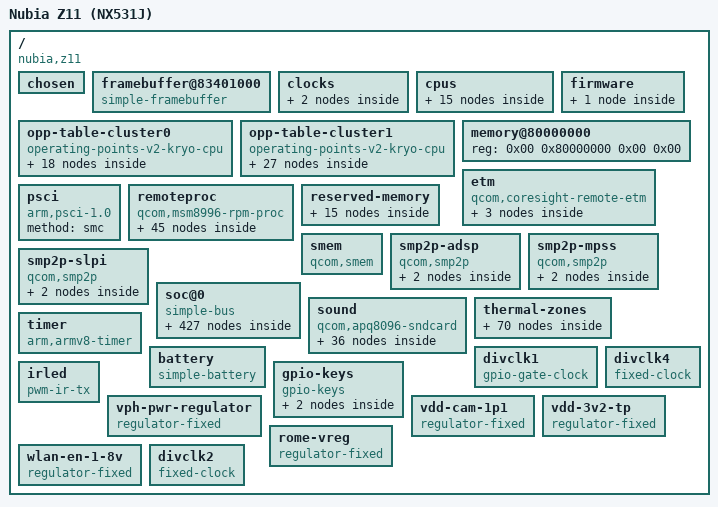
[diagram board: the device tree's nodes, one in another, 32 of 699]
/dts-v1/;

/ {
	interrupt-parent = <0x01>;
	#address-cells = <0x02>;
	#size-cells = <0x02>;
	model = "Nubia Z11 (NX531J)";
	compatible = "nubia,z11", "qcom,msm8996";
	chassis-type = "handset";
	qcom,msm-id = <0xf6 0x30001>;
	qcom,pmic-id = <0x20009 0x2000a 0x00 0x00>;
	qcom,board-id = <0x1f 0x00 0x20 0x00>;

	chosen {
	};

	framebuffer@83401000 {
		compatible = "simple-framebuffer";
		reg = <0x00 0x83401000 0x00 0x7e9000>;
		width = <0x438>;
		height = <0x780>;
		stride = <0x10e0>;
		format = "a8r8g8b8";
		status = "okay";
	};

	clocks {

		xo-board {
			compatible = "fixed-clock";
			#clock-cells = <0x00>;
			clock-frequency = <0x124f800>;
			clock-output-names = "xo_board";
			phandle = <0x12>;
		};

		sleep-clk {
			compatible = "fixed-clock";
			#clock-cells = <0x00>;
			clock-frequency = <0x7ffc>;
			clock-output-names = "sleep_clk";
			phandle = <0x20>;
		};
	};

	cpus {
		#address-cells = <0x02>;
		#size-cells = <0x00>;

		cpu@0 {
			device_type = "cpu";
			compatible = "qcom,kryo";
			reg = <0x00 0x00>;
			enable-method = "psci";
			cpu-idle-states = <0x02>;
			capacity-dmips-mhz = <0x400>;
			clocks = <0x03 0x00>;
			interconnects = <0x04 0x00 0x04 0x01>;
			operating-points-v2 = <0x05>;
			#cooling-cells = <0x02>;
			next-level-cache = <0x06>;
			phandle = <0x09>;

			l2-cache {
				compatible = "cache";
				cache-level = <0x02>;
				cache-unified;
				phandle = <0x06>;
			};
		};

		cpu@1 {
			device_type = "cpu";
			compatible = "qcom,kryo";
			reg = <0x00 0x01>;
			enable-method = "psci";
			cpu-idle-states = <0x02>;
			capacity-dmips-mhz = <0x400>;
			clocks = <0x03 0x00>;
			interconnects = <0x04 0x00 0x04 0x01>;
			operating-points-v2 = <0x05>;
			#cooling-cells = <0x02>;
			next-level-cache = <0x06>;
			phandle = <0x0a>;
		};

		cpu@100 {
			device_type = "cpu";
			compatible = "qcom,kryo";
			reg = <0x00 0x100>;
			enable-method = "psci";
			cpu-idle-states = <0x02>;
			capacity-dmips-mhz = <0x400>;
			clocks = <0x03 0x01>;
			interconnects = <0x04 0x00 0x04 0x01>;
			operating-points-v2 = <0x07>;
			#cooling-cells = <0x02>;
			next-level-cache = <0x08>;
			phandle = <0x0b>;

			l2-cache {
				compatible = "cache";
				cache-level = <0x02>;
				cache-unified;
				phandle = <0x08>;
			};
		};

		cpu@101 {
			device_type = "cpu";
			compatible = "qcom,kryo";
			reg = <0x00 0x101>;
			enable-method = "psci";
			cpu-idle-states = <0x02>;
			capacity-dmips-mhz = <0x400>;
			clocks = <0x03 0x01>;
			interconnects = <0x04 0x00 0x04 0x01>;
			operating-points-v2 = <0x07>;
			#cooling-cells = <0x02>;
			next-level-cache = <0x08>;
			phandle = <0x0c>;
		};

		cpu-map {

			cluster0 {

				core0 {
					cpu = <0x09>;
				};

				core1 {
					cpu = <0x0a>;
				};
			};

			cluster1 {

				core0 {
					cpu = <0x0b>;
				};

				core1 {
					cpu = <0x0c>;
				};
			};
		};

		idle-states {
			entry-method = "psci";

			cpu-sleep-0 {
				compatible = "arm,idle-state";
				idle-state-name = "standalone-power-collapse";
				arm,psci-suspend-param = <0x04>;
				entry-latency-us = <0x82>;
				exit-latency-us = <0x50>;
				min-residency-us = <0x12c>;
				phandle = <0x02>;
			};
		};
	};

	opp-table-cluster0 {
		compatible = "operating-points-v2-kryo-cpu";
		nvmem-cells = <0x0d>;
		opp-shared;
		phandle = <0x05>;

		opp-307200000 {
			opp-hz = <0x00 0x124f8000>;
			opp-supported-hw = <0x0f>;
			clock-latency-ns = <0x30d40>;
			opp-peak-kBps = <0x4b000>;
		};

		opp-422400000 {
			opp-hz = <0x00 0x192d5000>;
			opp-supported-hw = <0x0f>;
			clock-latency-ns = <0x30d40>;
			opp-peak-kBps = <0x4b000>;
		};

		opp-480000000 {
			opp-hz = <0x00 0x1c9c3800>;
			opp-supported-hw = <0x0f>;
			clock-latency-ns = <0x30d40>;
			opp-peak-kBps = <0x4b000>;
		};

		opp-556800000 {
			opp-hz = <0x00 0x21301800>;
			opp-supported-hw = <0x0f>;
			clock-latency-ns = <0x30d40>;
			opp-peak-kBps = <0x4b000>;
		};

		opp-652800000 {
			opp-hz = <0x00 0x26e8f000>;
			opp-supported-hw = <0x0f>;
			clock-latency-ns = <0x30d40>;
			opp-peak-kBps = <0x5dc00>;
		};

		opp-729600000 {
			opp-hz = <0x00 0x2b7cd000>;
			opp-supported-hw = <0x0f>;
			clock-latency-ns = <0x30d40>;
			opp-peak-kBps = "", "\a\b";
		};

		opp-844800000 {
			opp-hz = <0x00 0x325aa000>;
			opp-supported-hw = <0x0f>;
			clock-latency-ns = <0x30d40>;
			opp-peak-kBps = "", "\b4";
		};

		opp-960000000 {
			opp-hz = <0x00 0x39387000>;
			opp-supported-hw = <0x0f>;
			clock-latency-ns = <0x30d40>;
			opp-peak-kBps = "", "\nA";
		};

		opp-1036800000 {
			opp-hz = <0x00 0x3dcc5000>;
			opp-supported-hw = <0x0f>;
			clock-latency-ns = <0x30d40>;
			opp-peak-kBps = "", "\nA";
		};

		opp-1113600000 {
			opp-hz = <0x00 0x42603000>;
			opp-supported-hw = <0x0f>;
			clock-latency-ns = <0x30d40>;
			opp-peak-kBps = <0xc9900>;
		};

		opp-1190400000 {
			opp-hz = <0x00 0x46f41000>;
			opp-supported-hw = <0x0f>;
			clock-latency-ns = <0x30d40>;
			opp-peak-kBps = <0xc9900>;
		};

		opp-1228800000 {
			opp-hz = <0x00 0x493e0000>;
			opp-supported-hw = <0x0f>;
			clock-latency-ns = <0x30d40>;
			opp-peak-kBps = <0xdc500>;
		};

		opp-1324800000 {
			opp-hz = <0x00 0x4ef6d800>;
			opp-supported-hw = <0x0d>;
			clock-latency-ns = <0x30d40>;
			opp-peak-kBps = <0x101d00>;
		};

		opp-1363200000 {
			opp-hz = <0x00 0x5140c800>;
			opp-supported-hw = <0x02>;
			clock-latency-ns = <0x30d40>;
			opp-peak-kBps = <0x114900>;
		};

		opp-1401600000 {
			opp-hz = <0x00 0x538ab800>;
			opp-supported-hw = <0x0d>;
			clock-latency-ns = <0x30d40>;
			opp-peak-kBps = <0x114900>;
		};

		opp-1478400000 {
			opp-hz = <0x00 0x581e9800>;
			opp-supported-hw = <0x09>;
			clock-latency-ns = <0x30d40>;
			opp-peak-kBps = <0x122a00>;
		};

		opp-1497600000 {
			opp-hz = <0x00 0x59439000>;
			opp-supported-hw = <0x04>;
			clock-latency-ns = <0x30d40>;
			opp-peak-kBps = <0x13ec00>;
		};

		opp-1593600000 {
			opp-hz = <0x00 0x5efc6800>;
			opp-supported-hw = <0x09>;
			clock-latency-ns = <0x30d40>;
			opp-peak-kBps = <0x151800>;
		};
	};

	opp-table-cluster1 {
		compatible = "operating-points-v2-kryo-cpu";
		nvmem-cells = <0x0d>;
		opp-shared;
		phandle = <0x07>;

		opp-307200000 {
			opp-hz = <0x00 0x124f8000>;
			opp-supported-hw = <0x0f>;
			clock-latency-ns = <0x30d40>;
			opp-peak-kBps = <0x4b000>;
		};

		opp-403200000 {
			opp-hz = <0x00 0x18085800>;
			opp-supported-hw = <0x0f>;
			clock-latency-ns = <0x30d40>;
			opp-peak-kBps = <0x4b000>;
		};

		opp-480000000 {
			opp-hz = <0x00 0x1c9c3800>;
			opp-supported-hw = <0x0f>;
			clock-latency-ns = <0x30d40>;
			opp-peak-kBps = <0x4b000>;
		};

		opp-556800000 {
			opp-hz = <0x00 0x21301800>;
			opp-supported-hw = <0x0f>;
			clock-latency-ns = <0x30d40>;
			opp-peak-kBps = <0x4b000>;
		};

		opp-652800000 {
			opp-hz = <0x00 0x26e8f000>;
			opp-supported-hw = <0x0f>;
			clock-latency-ns = <0x30d40>;
			opp-peak-kBps = <0x4b000>;
		};

		opp-729600000 {
			opp-hz = <0x00 0x2b7cd000>;
			opp-supported-hw = <0x0f>;
			clock-latency-ns = <0x30d40>;
			opp-peak-kBps = <0x4b000>;
		};

		opp-806400000 {
			opp-hz = <0x00 0x3010b000>;
			opp-supported-hw = <0x0f>;
			clock-latency-ns = <0x30d40>;
			opp-peak-kBps = <0x5dc00>;
		};

		opp-883200000 {
			opp-hz = <0x00 0x34a49000>;
			opp-supported-hw = <0x0f>;
			clock-latency-ns = <0x30d40>;
			opp-peak-kBps = "", "\a\b";
		};

		opp-940800000 {
			opp-hz = <0x00 0x38137800>;
			opp-supported-hw = <0x0f>;
			clock-latency-ns = <0x30d40>;
			opp-peak-kBps = "", "\b4";
		};

		opp-1036800000 {
			opp-hz = <0x00 0x3dcc5000>;
			opp-supported-hw = <0x0f>;
			clock-latency-ns = <0x30d40>;
			opp-peak-kBps = <0x91500>;
		};

		opp-1113600000 {
			opp-hz = <0x00 0x42603000>;
			opp-supported-hw = <0x0f>;
			clock-latency-ns = <0x30d40>;
			opp-peak-kBps = "", "\nA";
		};

		opp-1190400000 {
			opp-hz = <0x00 0x46f41000>;
			opp-supported-hw = <0x0f>;
			clock-latency-ns = <0x30d40>;
			opp-peak-kBps = "", "\nA";
		};

		opp-1248000000 {
			opp-hz = <0x00 0x4a62f800>;
			opp-supported-hw = <0x0f>;
			clock-latency-ns = <0x30d40>;
			opp-peak-kBps = "", "\vm";
		};

		opp-1324800000 {
			opp-hz = <0x00 0x4ef6d800>;
			opp-supported-hw = <0x0f>;
			clock-latency-ns = <0x30d40>;
			opp-peak-kBps = <0xc9900>;
		};

		opp-1401600000 {
			opp-hz = <0x00 0x538ab800>;
			opp-supported-hw = <0x0f>;
			clock-latency-ns = <0x30d40>;
			opp-peak-kBps = <0xdc500>;
		};

		opp-1478400000 {
			opp-hz = <0x00 0x581e9800>;
			opp-supported-hw = <0x0f>;
			clock-latency-ns = <0x30d40>;
			opp-peak-kBps = <0xef100>;
		};

		opp-1555200000 {
			opp-hz = <0x00 0x5cb27800>;
			opp-supported-hw = <0x0f>;
			clock-latency-ns = <0x30d40>;
			opp-peak-kBps = <0x101d00>;
		};

		opp-1632000000 {
			opp-hz = <0x00 0x61465800>;
			opp-supported-hw = <0x0f>;
			clock-latency-ns = <0x30d40>;
			opp-peak-kBps = <0x122a00>;
		};

		opp-1708800000 {
			opp-hz = <0x00 0x65da3800>;
			opp-supported-hw = <0x0f>;
			clock-latency-ns = <0x30d40>;
			opp-peak-kBps = <0x12c000>;
		};

		opp-1785600000 {
			opp-hz = <0x00 0x6a6e1800>;
			opp-supported-hw = <0x0f>;
			clock-latency-ns = <0x30d40>;
			opp-peak-kBps = <0x13ec00>;
		};

		opp-1804800000 {
			opp-hz = <0x00 0x6b931000>;
			opp-supported-hw = <0x0e>;
			clock-latency-ns = <0x30d40>;
			opp-peak-kBps = <0x13ec00>;
		};

		opp-1824000000 {
			opp-hz = <0x00 0x6cb80800>;
			opp-supported-hw = <0x01>;
			clock-latency-ns = <0x30d40>;
			opp-peak-kBps = <0x151800>;
		};

		opp-1900800000 {
			opp-hz = <0x00 0x714be800>;
			opp-supported-hw = <0x04>;
			clock-latency-ns = <0x30d40>;
			opp-peak-kBps = <0x13ec00>;
		};

		opp-1920000000 {
			opp-hz = <0x00 0x7270e000>;
			opp-supported-hw = <0x01>;
			clock-latency-ns = <0x30d40>;
			opp-peak-kBps = <0x164400>;
		};

		opp-1996800000 {
			opp-hz = <0x00 0x7704c000>;
			opp-supported-hw = <0x01>;
			clock-latency-ns = <0x30d40>;
			opp-peak-kBps = <0x185100>;
		};

		opp-2073600000 {
			opp-hz = <0x00 0x7b98a000>;
			opp-supported-hw = <0x01>;
			clock-latency-ns = <0x30d40>;
			opp-peak-kBps = <0x185100>;
		};

		opp-2150400000 {
			opp-hz = <0x00 0x802c8000>;
			opp-supported-hw = <0x01>;
			clock-latency-ns = <0x30d40>;
			opp-peak-kBps = <0x185100>;
		};
	};

	firmware {

		scm {
			compatible = "qcom,scm-msm8996", "qcom,scm";
			qcom,dload-mode = <0x0e 0x13000>;
		};
	};

	memory@80000000 {
		device_type = "memory";
		reg = <0x00 0x80000000 0x00 0x00>;
	};

	etm {
		compatible = "qcom,coresight-remote-etm";

		out-ports {

			port {

				endpoint {
					remote-endpoint = <0x0f>;
					phandle = <0x6e>;
				};
			};
		};
	};

	psci {
		compatible = "arm,psci-1.0";
		method = "smc";
	};

	remoteproc {
		compatible = "qcom,msm8996-rpm-proc", "qcom,rpm-proc";

		glink-edge {
			compatible = "qcom,glink-rpm";
			interrupts = <0x00 0xa8 0x01>;
			qcom,rpm-msg-ram = <0x10>;
			mboxes = <0x11 0x00>;

			rpm-requests {
				compatible = "qcom,rpm-msm8996", "qcom,glink-smd-rpm";
				qcom,glink-channels = "rpm_requests";

				clock-controller {
					compatible = "qcom,rpmcc-msm8996", "qcom,rpmcc";
					#clock-cells = <0x01>;
					clocks = <0x12>;
					clock-names = "xo";
					phandle = <0x1f>;
				};

				power-controller {
					compatible = "qcom,msm8996-rpmpd";
					#power-domain-cells = <0x01>;
					operating-points-v2 = <0x13>;
					phandle = <0x60>;

					opp-table {
						compatible = "operating-points-v2";
						phandle = <0x13>;

						opp1 {
							opp-level = <0x01>;
						};

						opp2 {
							opp-level = <0x02>;
						};

						opp3 {
							opp-level = <0x03>;
						};

						opp4 {
							opp-level = <0x04>;
						};

						opp5 {
							opp-level = <0x05>;
						};

						opp6 {
							opp-level = <0x06>;
						};
					};
				};

				regulators-0 {
					compatible = "qcom,rpm-pm8994-regulators";
					vdd_s1-supply = <0x14>;
					vdd_s2-supply = <0x14>;
					vdd_s3-supply = <0x14>;
					vdd_s4-supply = <0x14>;
					vdd_s5-supply = <0x14>;
					vdd_s6-supply = <0x14>;
					vdd_s7-supply = <0x14>;
					vdd_s8-supply = <0x14>;
					vdd_s9-supply = <0x14>;
					vdd_s10-supply = <0x14>;
					vdd_s11-supply = <0x14>;
					vdd_s12-supply = <0x14>;
					vdd_l1-supply = <0x15>;
					vdd_l2_l26_l28-supply = <0x16>;
					vdd_l3_l11-supply = <0x16>;
					vdd_l4_l27_l31-supply = <0x16>;
					vdd_l5_l7-supply = <0x17>;
					vdd_l6_l12_l32-supply = <0x17>;
					vdd_l8_l16_l30-supply = <0x14>;
					vdd_l9_l10_l18_l22-supply = <0x18>;
					vdd_l13_l19_l23_l24-supply = <0x18>;
					vdd_l14_l15-supply = <0x17>;
					vdd_l17_l29-supply = <0x18>;
					vdd_l20_l21-supply = <0x18>;
					vdd_l25-supply = <0x16>;
					vdd_lvs1_2-supply = <0x19>;

					s3 {
						regulator-name = "vreg_s3a_1p3";
						regulator-min-microvolt = <0x13d620>;
						regulator-max-microvolt = <0x13d620>;
						regulator-always-on;
						phandle = <0x16>;
					};

					s4 {
						regulator-name = "vreg_s4a_1p8";
						regulator-min-microvolt = <0x1b7740>;
						regulator-max-microvolt = <0x1b7740>;
						regulator-allow-set-load;
						regulator-always-on;
						phandle = <0x19>;
					};

					s5 {
						regulator-name = "vreg_s5a_2p15";
						regulator-min-microvolt = <0x20ce70>;
						regulator-max-microvolt = <0x20ce70>;
						phandle = <0x17>;
					};

					s7 {
						regulator-name = "vreg_s7a_0p8";
						regulator-min-microvolt = "", "\f5";
						regulator-max-microvolt = "", "\f5";
					};

					l1 {
						regulator-name = "vreg_l1a_1p0";
						regulator-min-microvolt = <0xf4240>;
						regulator-max-microvolt = <0xf4240>;
					};

					l2 {
						regulator-name = "vreg_l2a_1p25";
						regulator-min-microvolt = <0x1312d0>;
						regulator-max-microvolt = <0x1312d0>;
						phandle = <0x39>;
					};

					l4 {
						regulator-name = "vreg_l4a_1p225";
						regulator-min-microvolt = <0x12b128>;
						regulator-max-microvolt = <0x12b128>;
					};

					l6 {
						regulator-name = "vreg_l6a_1p8";
						regulator-min-microvolt = <0x1b7740>;
						regulator-max-microvolt = <0x1b7740>;
						phandle = <0xa9>;
					};

					l8 {
						regulator-name = "vreg_l8a_1p8";
						regulator-min-microvolt = <0x1b7740>;
						regulator-max-microvolt = <0x1b7740>;
					};

					l9 {
						regulator-name = "vreg_l9a_1p8";
						regulator-min-microvolt = <0x1b7740>;
						regulator-max-microvolt = <0x1b7740>;
					};

					l10 {
						regulator-name = "vreg_l10a_1p8";
						regulator-min-microvolt = <0x1b7740>;
						regulator-max-microvolt = <0x1b7740>;
					};

					l12 {
						regulator-name = "vreg_l12a_1p8";
						regulator-min-microvolt = <0x1b7740>;
						regulator-max-microvolt = <0x1b7740>;
						regulator-allow-set-load;
						phandle = <0x1e>;
					};

					l13 {
						regulator-name = "vreg_l13a_2p95";
						regulator-min-microvolt = <0x1b7740>;
						regulator-max-microvolt = <0x2d0370>;
					};

					l14 {
						regulator-name = "vreg_l14a_1p8";
						regulator-min-microvolt = <0x1b7740>;
						regulator-max-microvolt = <0x1b7740>;
						phandle = <0x34>;
					};

					l15 {
						regulator-name = "vreg_l15a_1p8";
						regulator-min-microvolt = <0x1b7740>;
						regulator-max-microvolt = <0x1b7740>;
					};

					l16 {
						regulator-name = "vreg_l16a_2p7";
						regulator-min-microvolt = <0x2932e0>;
						regulator-max-microvolt = <0x2932e0>;
					};

					l19 {
						regulator-name = "vreg_l19a_3p3";
						regulator-min-microvolt = <0x2dc6c0>;
						regulator-max-microvolt = <0x2dc6c0>;
						phandle = <0x33>;
					};

					l20 {
						regulator-name = "vreg_l20a_2p95";
						regulator-min-microvolt = <0x2d0370>;
						regulator-max-microvolt = <0x2d0370>;
						regulator-allow-set-load;
						phandle = <0x55>;
					};

					l21 {
						regulator-name = "vreg_l21a_2p95";
						regulator-min-microvolt = <0x325aa0>;
						regulator-max-microvolt = <0x325aa0>;
						regulator-always-on;
					};

					l23 {
						regulator-name = "vreg_l23a_2p8";
						regulator-min-microvolt = <0x2ab980>;
						regulator-max-microvolt = <0x2ab980>;
					};

					l24 {
						regulator-name = "vreg_l24a_3p075";
						regulator-min-microvolt = <0x2eebb8>;
						regulator-max-microvolt = <0x2eebb8>;
						phandle = <0x8c>;
					};

					l25 {
						regulator-name = "vreg_l25a_1p2";
						regulator-min-microvolt = <0x124f80>;
						regulator-max-microvolt = <0x124f80>;
						regulator-allow-set-load;
						phandle = <0x56>;
					};

					l27 {
						regulator-name = "vreg_l27a_1p2";
						regulator-min-microvolt = <0x124f80>;
						regulator-max-microvolt = <0x124f80>;
					};

					l28 {
						regulator-name = "vreg_l28a_0p925";
						regulator-min-microvolt = <0xe1d48>;
						regulator-max-microvolt = <0xe1d48>;
						regulator-allow-set-load;
						phandle = <0x1d>;
					};

					l30 {
						regulator-name = "vreg_l30a_1p8";
						regulator-min-microvolt = <0x1b7740>;
						regulator-max-microvolt = <0x1b7740>;
						regulator-always-on;
					};

					l32 {
						regulator-name = "vreg_l32a_1p8";
						regulator-min-microvolt = <0x1b7740>;
						regulator-max-microvolt = <0x1b7740>;
					};

					lvs1 {
						regulator-name = "vreg_lvs1a_1p8";
						regulator-min-microvolt = <0x1b7740>;
						regulator-max-microvolt = <0x1b7740>;
					};

					lvs2 {
						regulator-name = "vreg_lvs2a_1p8";
						regulator-min-microvolt = <0x1b7740>;
						regulator-max-microvolt = <0x1b7740>;
						phandle = <0x61>;
					};

					l17 {
						regulator-name = "vreg_l17a_2p8";
						regulator-min-microvolt = <0x2625a0>;
						regulator-max-microvolt = <0x2625a0>;
					};

					l29 {
						regulator-name = "vreg_l29a_2p7";
						regulator-min-microvolt = <0x2ab980>;
						regulator-max-microvolt = <0x2ab980>;
					};
				};

				regulators-1 {
					compatible = "qcom,rpm-pmi8994-regulators";
					vdd_s1-supply = <0x14>;
					vdd_s2-supply = <0x14>;
					vdd_s3-supply = <0x14>;
					vdd_bst_byp-supply = <0x14>;

					s1 {
						regulator-name = "vreg_s1b_1p025";
						regulator-min-microvolt = <0xfa3e8>;
						regulator-max-microvolt = <0xfa3e8>;
						phandle = <0x15>;
					};

					boost-bypass {
						regulator-name = "vph_pwr_bbyp";
						regulator-min-microvolt = <0x3010b0>;
						regulator-max-microvolt = <0x36ee80>;
						phandle = <0x18>;
					};
				};
			};
		};
	};

	reserved-memory {
		#address-cells = <0x02>;
		#size-cells = <0x02>;
		ranges;

		memory@85800000 {
			reg = <0x00 0x85800000 0x00 0x600000>;
			no-map;
				splash_region: splash@83400000 {
			reg = <0x00 0x83400000 0x00 0x23ff000>;
		};
};

		memory@85e00000 {
			reg = <0x00 0x85e00000 0x00 0x200000>;
			no-map;
		};

		smem-mem@86000000 {
			reg = <0x00 0x86000000 0x00 0x200000>;
			no-map;
			phandle = <0x1a>;
		};

		memory@86200000 {
			reg = <0x00 0x86200000 0x00 0x2600000>;
			no-map;
		};

		mpss-metadata {
			alloc-ranges = <0x00 0xa0000000 0x00 0x20000000>;
			size = <0x00 0x4000>;
			no-map;
			phandle = <0x67>;
		};

		memory@88800000 {
			reg = <0x00 0x88800000 0x00 0x1400000>;
			no-map;
		};

		mpss@89c00000 {
			reg = <0x00 0x89c00000 0x00 0x6200000>;
			no-map;
			phandle = <0x66>;
		};

		adsp@8fe00000 {
			reg = <0x00 0x8fe00000 0x00 0x1b00000>;
			no-map;
			phandle = <0xb7>;
		};

		slpi@91900000 {
			reg = <0x00 0x91900000 0x00 0xa00000>;
			no-map;
			phandle = <0x5e>;
		};

		gpu@92300000 {
			compatible = "shared-dma-pool";
			reg = <0x00 0x92300000 0x00 0x2000>;
			no-map;
			phandle = <0x43>;
		};

		venus@92400000 {
			reg = <0x00 0x92400000 0x00 0x500000>;
			no-map;
			phandle = <0x5c>;
		};

		ramoops@92900000 {
			compatible = "ramoops";
			reg = <0x00 0x92900000 0x00 0x100000>;
			no-map;
			record-size = <0x8000>;
			console-size = <0x80000>;
			ftrace-size = <0x20000>;
			pmsg-size = <0x40000>;
		};

		rmtfs@f6c00000 {
			compatible = "qcom,rmtfs-mem";
			reg = <0x00 0xf6c00000 0x00 0x200000>;
			no-map;
			qcom,client-id = <0x01>;
			qcom,vmid = <0x0f>;
		};

		mba@f6f00000 {
			reg = <0x00 0xf6f00000 0x00 0x100000>;
			no-map;
			phandle = <0x65>;
		};
	};

	smem {
		compatible = "qcom,smem";
		memory-region = <0x1a>;
		hwlocks = <0x1b 0x03>;
	};

	smp2p-adsp {
		compatible = "qcom,smp2p";
		qcom,smem = <0x1bb 0x1ad>;
		interrupts = <0x00 0x9e 0x01>;
		mboxes = <0x11 0x0a>;
		qcom,local-pid = <0x00>;
		qcom,remote-pid = <0x02>;

		master-kernel {
			qcom,entry-name = "master-kernel";
			#qcom,smem-state-cells = <0x01>;
			phandle = <0xb8>;
		};

		slave-kernel {
			qcom,entry-name = "slave-kernel";
			interrupt-controller;
			#interrupt-cells = <0x02>;
			phandle = <0xb6>;
		};
	};

	smp2p-mpss {
		compatible = "qcom,smp2p";
		qcom,smem = <0x1b3 0x1ac>;
		interrupts = <0x00 0x1c3 0x01>;
		mboxes = <0x11 0x0e>;
		qcom,local-pid = <0x00>;
		qcom,remote-pid = <0x01>;

		master-kernel {
			qcom,entry-name = "master-kernel";
			#qcom,smem-state-cells = <0x01>;
			phandle = <0x63>;
		};

		slave-kernel {
			qcom,entry-name = "slave-kernel";
			interrupt-controller;
			#interrupt-cells = <0x02>;
			phandle = <0x62>;
		};
	};

	smp2p-slpi {
		compatible = "qcom,smp2p";
		qcom,smem = <0x1e1 0x1ae>;
		interrupts = <0x00 0xb2 0x01>;
		mboxes = <0x11 0x1a>;
		qcom,local-pid = <0x00>;
		qcom,remote-pid = <0x03>;

		master-kernel {
			qcom,entry-name = "master-kernel";
			#qcom,smem-state-cells = <0x01>;
			phandle = <0x5f>;
		};

		slave-kernel {
			qcom,entry-name = "slave-kernel";
			interrupt-controller;
			#interrupt-cells = <0x02>;
			phandle = <0x5d>;
		};
	};

	soc@0 {
		#address-cells = <0x01>;
		#size-cells = <0x01>;
		ranges = <0x00 0x00 0x00 0xffffffff>;
		compatible = "simple-bus";

		phy-wrapper@34000 {
			compatible = "qcom,msm8996-qmp-pcie-phy";
			reg = <0x34000 0x488>;
			#address-cells = <0x01>;
			#size-cells = <0x01>;
			ranges = <0x00 0x34000 0x4000>;
			clocks = <0x1c 0xc0 0x1c 0xbf 0x1c 0xd8>;
			clock-names = "aux", "cfg_ahb", "ref";
			resets = <0x1c 0x55 0x1c 0x65 0x1c 0x66>;
			reset-names = "phy", "common", "cfg";
			status = "okay";
			vdda-phy-supply = <0x1d>;
			vdda-pll-supply = <0x1e>;

			phy@1000 {
				reg = <0x1000 0x130 0x1200 0x200 0x1400 0x1dc>;
				clocks = <0x1c 0xb4>;
				clock-names = "pipe0";
				resets = <0x1c 0x50>;
				reset-names = "lane0";
				#clock-cells = <0x00>;
				clock-output-names = "pcie_0_pipe_clk_src";
				#phy-cells = <0x00>;
				phandle = <0x21>;
			};

			phy@2000 {
				reg = <0x2000 0x130 0x2200 0x200 0x2400 0x1dc>;
				clocks = <0x1c 0xb9>;
				clock-names = "pipe1";
				resets = <0x1c 0x52>;
				reset-names = "lane1";
				#clock-cells = <0x00>;
				clock-output-names = "pcie_1_pipe_clk_src";
				#phy-cells = <0x00>;
				phandle = <0x22>;
			};

			phy@3000 {
				reg = <0x3000 0x130 0x3200 0x200 0x3400 0x1dc>;
				clocks = <0x1c 0xbe>;
				clock-names = "pipe2";
				resets = <0x1c 0x54>;
				reset-names = "lane2";
				#clock-cells = <0x00>;
				clock-output-names = "pcie_2_pipe_clk_src";
				#phy-cells = <0x00>;
				phandle = <0x23>;
			};
		};

		sram@68000 {
			compatible = "qcom,rpm-msg-ram";
			reg = <0x68000 0x6000>;
			phandle = <0x10>;
		};

		qfprom@74000 {
			compatible = "qcom,msm8996-qfprom", "qcom,qfprom";
			reg = <0x74000 0x8ff>;
			#address-cells = <0x01>;
			#size-cells = <0x01>;

			hstx-trim@24e {
				reg = <0x24e 0x02>;
				bits = <0x05 0x04>;
				phandle = <0x8b>;
			};

			hstx-trim@24f {
				reg = <0x24f 0x01>;
				bits = <0x01 0x04>;
				phandle = <0x8d>;
			};

			speedbin@133 {
				reg = <0x133 0x01>;
				bits = <0x05 0x03>;
				phandle = <0x0d>;
			};
		};

		rng@83000 {
			compatible = "qcom,prng-ee";
			reg = <0x83000 0x1000>;
			clocks = <0x1c 0x98>;
			clock-names = "core";
		};

		clock-controller@300000 {
			compatible = "qcom,gcc-msm8996";
			#clock-cells = <0x01>;
			#reset-cells = <0x01>;
			#power-domain-cells = <0x01>;
			reg = <0x300000 0x90000>;
			clocks = <0x1f 0x00 0x1f 0x4a 0x20 0x21 0x22 0x23 0x24 0x25 0x00 0x25 0x01 0x25 0x02>;
			clock-names = "cxo", "cxo2", "sleep_clk", "pcie_0_pipe_clk_src", "pcie_1_pipe_clk_src", "pcie_2_pipe_clk_src", "usb3_phy_pipe_clk_src", "ufs_rx_symbol_0_clk_src", "ufs_rx_symbol_1_clk_src", "ufs_tx_symbol_0_clk_src";
			phandle = <0x1c>;
		};

		interconnect@408000 {
			compatible = "qcom,msm8996-bimc";
			reg = <0x408000 0x5a000>;
			#interconnect-cells = <0x01>;
			phandle = <0x2f>;
		};

		thermal-sensor@4a9000 {
			compatible = "qcom,msm8996-tsens", "qcom,tsens-v2";
			reg = <0x4a9000 0x1000 0x4a8000 0x1000>;
			#qcom,sensors = <0x0d>;
			interrupts = <0x00 0x1ca 0x04 0x00 0x1bd 0x04>;
			interrupt-names = "uplow", "critical";
			#thermal-sensor-cells = <0x01>;
			phandle = <0xbe>;
		};

		thermal-sensor@4ad000 {
			compatible = "qcom,msm8996-tsens", "qcom,tsens-v2";
			reg = <0x4ad000 0x1000 0x4ac000 0x1000>;
			#qcom,sensors = <0x08>;
			interrupts = <0x00 0xb8 0x04 0x00 0x1ae 0x04>;
			interrupt-names = "uplow", "critical";
			#thermal-sensor-cells = <0x01>;
			phandle = <0xc7>;
		};

		dma-controller@644000 {
			compatible = "qcom,bam-v1.7.0";
			reg = <0x644000 0x24000>;
			interrupts = <0x00 0xce 0x04>;
			clocks = <0x1c 0xa4>;
			clock-names = "bam_clk";
			#dma-cells = <0x01>;
			qcom,ee = <0x00>;
			qcom,controlled-remotely;
			phandle = <0x26>;
		};

		crypto@67a000 {
			compatible = "qcom,crypto-v5.4";
			reg = <0x67a000 0x6000>;
			clocks = <0x1c 0xa6 0x1c 0xa5 0x1c 0xa4>;
			clock-names = "iface", "bus", "core";
			dmas = <0x26 0x06 0x26 0x07>;
			dma-names = "rx", "tx";
		};

		interconnect@500000 {
			compatible = "qcom,msm8996-cnoc";
			reg = <0x500000 0x1000>;
			#interconnect-cells = <0x01>;
			phandle = <0x54>;
		};

		interconnect@524000 {
			compatible = "qcom,msm8996-snoc";
			reg = <0x524000 0x1c000>;
			#interconnect-cells = <0x01>;
			phandle = <0x87>;
		};

		interconnect@543000 {
			compatible = "qcom,msm8996-a0noc";
			reg = <0x543000 0x6000>;
			#interconnect-cells = <0x01>;
			clock-names = "aggre0_snoc_axi", "aggre0_cnoc_ahb", "aggre0_noc_mpu_cfg";
			clocks = <0x1c 0xcc 0x1c 0xcd 0x1c 0xe3>;
			power-domains = <0x1c 0x00>;
		};

		interconnect@562000 {
			compatible = "qcom,msm8996-a1noc";
			reg = <0x562000 0x5000>;
			#interconnect-cells = <0x01>;
		};

		interconnect@583000 {
			compatible = "qcom,msm8996-a2noc";
			reg = <0x583000 0x7000>;
			#interconnect-cells = <0x01>;
			clock-names = "aggre2_ufs_axi", "ufs_axi";
			clocks = <0x1c 0xd1 0x1c 0xc1>;
			phandle = <0x53>;
		};

		interconnect@5a4000 {
			compatible = "qcom,msm8996-mnoc";
			reg = <0x5a4000 0x1c000>;
			#interconnect-cells = <0x01>;
			clock-names = "iface";
			clocks = <0x27 0x10>;
			phandle = <0x2e>;
		};

		interconnect@5c0000 {
			compatible = "qcom,msm8996-pnoc";
			reg = <0x5c0000 0x3000>;
			#interconnect-cells = <0x01>;
			phandle = <0xaf>;
		};

		hwlock@740000 {
			compatible = "qcom,tcsr-mutex";
			reg = <0x740000 0x20000>;
			#hwlock-cells = <0x01>;
			phandle = <0x1b>;
		};

		syscon@760000 {
			compatible = "qcom,tcsr-msm8996", "syscon";
			reg = <0x760000 0x20000>;
			phandle = <0x64>;
		};

		syscon@7a0000 {
			compatible = "qcom,tcsr-msm8996", "syscon";
			reg = <0x7a0000 0x18000>;
			phandle = <0x0e>;
		};

		clock-controller@8c0000 {
			compatible = "qcom,mmcc-msm8996";
			#clock-cells = <0x01>;
			#reset-cells = <0x01>;
			#power-domain-cells = <0x01>;
			reg = <0x8c0000 0x40000>;
			clocks = <0x12 0x1c 0x01 0x1c 0x59 0x28 0x01 0x28 0x00 0x29 0x01 0x29 0x00 0x2a>;
			clock-names = "xo", "gpll0", "gcc_mmss_noc_cfg_ahb_clk", "dsi0pll", "dsi0pllbyte", "dsi1pll", "dsi1pllbyte", "hdmipll";
			assigned-clocks = <0x27 0x0f 0x27 0x03 0x27 0x07 0x27 0x09 0x27 0x0b>;
			assigned-clock-rates = <0x25317c00 0x30479e80 0x3a699d00 0x39387000 0x312c8040>;
			vdd-gfx-supply = <0x2b>;
			phandle = <0x27>;
		};

		display-subsystem@900000 {
			compatible = "qcom,mdss";
			reg = <0x900000 0x1000 0x9b0000 0x1040 0x9b8000 0x1040>;
			reg-names = "mdss_phys", "vbif_phys", "vbif_nrt_phys";
			power-domains = <0x27 0x0d>;
			interrupts = <0x00 0x53 0x04>;
			interrupt-controller;
			#interrupt-cells = <0x01>;
			clocks = <0x27 0x74 0x27 0x79>;
			clock-names = "iface", "core";
			resets = <0x27 0x1a>;
			#address-cells = <0x01>;
			#size-cells = <0x01>;
			ranges;
			status = "okay";
			phandle = <0x2c>;

			display-controller@901000 {
				compatible = "qcom,msm8996-mdp5", "qcom,mdp5";
				reg = <0x901000 0x90000>;
				reg-names = "mdp_phys";
				interrupt-parent = <0x2c>;
				interrupts = <0x00>;
				clocks = <0x27 0x74 0x27 0x76 0x27 0x79 0x27 0x5c 0x27 0x7b>;
				clock-names = "iface", "bus", "core", "iommu", "vsync";
				iommus = <0x2d 0x00>;
				assigned-clocks = <0x27 0x79 0x27 0x7b>;
				assigned-clock-rates = <0x11e1a300 0x124f800>;
				interconnects = <0x2e 0x03 0x2f 0x04 0x2e 0x04 0x2f 0x04 0x2e 0x05 0x2f 0x04>;
				interconnect-names = "mdp0-mem", "mdp1-mem", "rotator-mem";

				ports {
					#address-cells = <0x01>;
					#size-cells = <0x00>;

					port@0 {
						reg = <0x00>;

						endpoint {
							remote-endpoint = <0x30>;
							phandle = <0x40>;
						};
					};

					port@1 {
						reg = <0x01>;

						endpoint {
							remote-endpoint = <0x31>;
							phandle = <0x3a>;
						};
					};

					port@2 {
						reg = <0x02>;

						endpoint {
							remote-endpoint = <0x32>;
							phandle = <0x3f>;
						};
					};
				};
			};

			dsi@994000 {
				compatible = "qcom,msm8996-dsi-ctrl", "qcom,mdss-dsi-ctrl";
				reg = <0x994000 0x400>;
				reg-names = "dsi_ctrl";
				interrupt-parent = <0x2c>;
				interrupts = <0x04>;
				clocks = <0x27 0x79 0x27 0x7d 0x27 0x74 0x27 0x76 0x27 0x41 0x27 0x77 0x27 0x7f>;
				clock-names = "mdp_core", "byte", "iface", "bus", "core_mmss", "pixel", "core";
				assigned-clocks = <0x27 0x21 0x27 0x1b>;
				assigned-clock-parents = <0x28 0x00 0x28 0x01>;
				phys = <0x28>;
				status = "okay";
				#address-cells = <0x01>;
				#size-cells = <0x00>;
				vdda-supply = <0x33>;
				vcca-supply = <0x1d>;
				vddio-supply = <0x34>;
				pinctrl-names = "default", "sleep";
				pinctrl-0 = <0x35 0x36>;
				pinctrl-1 = <0x37 0x38>;
				vdd-supply = <0x39>;

				ports {
					#address-cells = <0x01>;
					#size-cells = <0x00>;

					port@0 {
						reg = <0x00>;

						endpoint {
							remote-endpoint = <0x3a>;
							phandle = <0x31>;
						};
					};

					port@1 {
						reg = <0x01>;

						endpoint {
							status = "okay";
							data-lanes = <0x00 0x01 0x02 0x03>;
							remote-endpoint = <0x3b>;
							phandle = <0x3e>;
						};
					};
				};

				panel@0 {
					compatible = "jdi,fhd-r63452";
					reg = <0x00>;
					reset-gpios = <0x3c 0x08 0x01>;
					backlight = <0x3d>;

					port {

						endpoint {
							remote-endpoint = <0x3e>;
							phandle = <0x3b>;
						};
					};
				};
			};

			phy@994400 {
				compatible = "qcom,dsi-phy-14nm";
				reg = <0x994400 0x100 0x994500 0x300 0x994800 0x188>;
				reg-names = "dsi_phy", "dsi_phy_lane", "dsi_pll";
				#clock-cells = <0x01>;
				#phy-cells = <0x00>;
				clocks = <0x27 0x74 0x1f 0x00>;
				clock-names = "iface", "ref";
				status = "okay";
				vcca-supply = <0x1d>;
				phandle = <0x28>;
			};

			dsi@996000 {
				compatible = "qcom,msm8996-dsi-ctrl", "qcom,mdss-dsi-ctrl";
				reg = <0x996000 0x400>;
				reg-names = "dsi_ctrl";
				interrupt-parent = <0x2c>;
				interrupts = <0x05>;
				clocks = <0x27 0x79 0x27 0x7e 0x27 0x74 0x27 0x76 0x27 0x41 0x27 0x78 0x27 0x80>;
				clock-names = "mdp_core", "byte", "iface", "bus", "core_mmss", "pixel", "core";
				assigned-clocks = <0x27 0x22 0x27 0x1c>;
				assigned-clock-parents = <0x29 0x00 0x29 0x01>;
				phys = <0x29>;
				status = "disabled";
				#address-cells = <0x01>;
				#size-cells = <0x00>;

				ports {
					#address-cells = <0x01>;
					#size-cells = <0x00>;

					port@0 {
						reg = <0x00>;

						endpoint {
							remote-endpoint = <0x3f>;
							phandle = <0x32>;
						};
					};

					port@1 {
						reg = <0x01>;

						endpoint {
						};
					};
				};
			};

			phy@996400 {
				compatible = "qcom,dsi-phy-14nm";
				reg = <0x996400 0x100 0x996500 0x300 0x996800 0x188>;
				reg-names = "dsi_phy", "dsi_phy_lane", "dsi_pll";
				#clock-cells = <0x01>;
				#phy-cells = <0x00>;
				clocks = <0x27 0x74 0x1f 0x00>;
				clock-names = "iface", "ref";
				status = "disabled";
				phandle = <0x29>;
			};

			hdmi-tx@9a0000 {
				compatible = "qcom,hdmi-tx-8996";
				reg = <0x9a0000 0x50c 0x70000 0x6158 0x9e0000 0xfff>;
				reg-names = "core_physical", "qfprom_physical", "hdcp_physical";
				interrupt-parent = <0x2c>;
				interrupts = <0x08>;
				clocks = <0x27 0x79 0x27 0x74 0x27 0x7c 0x27 0x75 0x27 0x7a>;
				clock-names = "mdp_core", "iface", "core", "alt_iface", "extp";
				phys = <0x2a>;
				#sound-dai-cells = <0x01>;
				status = "disabled";

				ports {
					#address-cells = <0x01>;
					#size-cells = <0x00>;

					port@0 {
						reg = <0x00>;

						endpoint {
							remote-endpoint = <0x40>;
							phandle = <0x30>;
						};
					};
				};
			};

			phy@9a0600 {
				#phy-cells = <0x00>;
				compatible = "qcom,hdmi-phy-8996";
				reg = <0x9a0600 0x1c4 0x9a0a00 0x124 0x9a0c00 0x124 0x9a0e00 0x124 0x9a1000 0x124 0x9a1200 0xc8>;
				reg-names = "hdmi_pll", "hdmi_tx_l0", "hdmi_tx_l1", "hdmi_tx_l2", "hdmi_tx_l3", "hdmi_phy";
				clocks = <0x27 0x74 0x1c 0xd6 0x12>;
				clock-names = "iface", "ref", "xo";
				#clock-cells = <0x00>;
				status = "disabled";
				phandle = <0x2a>;
			};
		};

		gpu@b00000 {
			compatible = "qcom,adreno-530.2", "qcom,adreno";
			reg = <0xb00000 0x3f000>;
			reg-names = "kgsl_3d0_reg_memory";
			interrupts = <0x00 0x12c 0x04>;
			clocks = <0x27 0x66 0x27 0x68 0x27 0x67 0x1c 0xa8 0x1c 0x5a>;
			clock-names = "core", "iface", "rbbmtimer", "mem", "mem_iface";
			interconnects = <0x2f 0x01 0x2f 0x04>;
			interconnect-names = "gfx-mem";
			power-domains = <0x27 0x0e>;
			iommus = <0x41 0x00>;
			nvmem-cells = <0x0d>;
			nvmem-cell-names = "speed_bin";
			operating-points-v2 = <0x42>;
			status = "okay";
			#cooling-cells = <0x02>;
			phandle = <0xc9>;

			opp-table {
				compatible = "operating-points-v2";
				phandle = <0x42>;

				opp-624000000 {
					opp-hz = <0x00 0x25317c00>;
					opp-supported-hw = <0x09>;
				};

				opp-560000000 {
					opp-hz = <0x00 0x2160ec00>;
					opp-supported-hw = <0x0d>;
				};

				opp-510000000 {
					opp-hz = <0x00 0x1e65fb80>;
					opp-supported-hw = <0xff>;
				};

				opp-401800000 {
					opp-hz = <0x00 0x17f2fb40>;
					opp-supported-hw = <0xff>;
				};

				opp-315000000 {
					opp-hz = <0x00 0x12c684c0>;
					opp-supported-hw = <0xff>;
				};

				opp-214000000 {
					opp-hz = <0x00 0xcc16180>;
					opp-supported-hw = <0xff>;
				};

				opp-133000000 {
					opp-hz = <0x00 0x7ed6b40>;
					opp-supported-hw = <0xff>;
				};
			};

			zap-shader {
				memory-region = <0x43>;
				firmware-name = "qcom/msm8996/gemini/a530_zap.mbn";
			};
		};

		pinctrl@1010000 {
			compatible = "qcom,msm8996-pinctrl";
			reg = <0x1010000 0x300000>;
			interrupts = <0x00 0xd0 0x04>;
			gpio-controller;
			gpio-ranges = <0x3c 0x00 0x00 0x96>;
			#gpio-cells = <0x02>;
			interrupt-controller;
			#interrupt-cells = <0x02>;
			gpio-line-names = "ESE_SPI_MOSI", "ESE_SPI_MISO", "ERR_INT_N", "ESE_SPI_CLK", "MSM_UART_TX", "MSM_UART_RX", "NFC_I2C_SDA", "NFC_I2C_SCL", "LCD0_RESET_N", "NFC_IRQ", "LCD_TE", "LCD_ID_DET1", "NFC_DISABLE", "CAM_MCLK0", "NC", "CAM_MCLK2", "ESE_PWR_REQ", "CCI_I2C_SDA0", "CCI_I2C_SCL0", "CCI_I2C_SDA1", "CCI_I2C_SCL1", "NFC_DWL_REQ", "CCI_TIMER1", "WEBCAM1_RESET_N", "ESE_IRQ", "NC", "WEBCAM1_STANDBY", "NC", "NC", "NC", "CAM1_RST_N", "NC", "NC", "NC", "FP_DOME_SW", "PCI_E0_RST_N", "PCI_E0_CLKREQ_N", "PCI_E0_WAKE", "FM_INT_N", "FM_RESET_N", "NC", "QCA_UART_TXD", "QCA_UART_RXD", "QCA_UART_CTS", "QCA_UART_RTS", "MAWC_UART_TX", "MAWC_UART_RX", "NC", "NC", "AUDIO_SWITCH_EN", "FP_SPI_RST", "TYPEC_I2C_SDA", "TYPEC_I2C_SCL", "CODEC_INT2_N", "CODEC_INT1_N", "APPS_I2C7_SDA", "APPS_I2C7_SCL", "FORCE_USB_BOOT", "SPKR_I2S_BCK", "SPKR_I2S_WS", "SPKR_I2S_DOUT", "SPKR_I2S_DIN", "ESE_RSTN", "TYPEC_INT", "CODEC_RESET_N", "PCM_CLK", "PCM_SYNC", "PCM_DIN", "PCM_DOUT", "HIFI_CLK", "SLIMBUS_CLK", "SLIMBUS_DATA0", "SLIMBUS_DATA1", "LDO_5V_IN_EN", "NC", "FM_I2S_CLK", "FM_I2S_SYNC", "FM_I2S_DATA", "FM_STATUS", "NC", "SENSOR_RESET_N", "FP_SPI_MOSI", "FP_SPI_MISO", "FP_SPI_CS_N", "FP_SPI_CLK", "NC", "CAM_VDD_1P05_EN", "MSM_TS_I2C_SDA", "MSM_TS_I2C_SCL", "TS_RESOUT_N", "ESE_SPI_CS_N", "NC", "NC", "HAPTICS_EN", "NC", "NC", "NC", "NC", "GRFC_1", "NC", "GRFC_3", "GRFC_4", "NC", "NC", "GRFC_7", "UIM2_DATA", "UIM2_CLK", "UIM2_RESET", "UIM2_PRESENT", "UIM1_DATA", "UIM1_CLK", "UIM1_RESET", "UIM1_PRESENT", "UIM_BATT_ALARM", "GRFC_8", "GRFC_9", "TX_GTR_THRES", "ACCEL_INT", "GYRO_INT", "COMPASS_INT", "PROXIMITY_INT_N", "FP_IRQ", "NC", "HALL_INTR2", "HALL_INTR1", "TS_INT_N", "NC", "GRFC_11", "NC", "EXT_GPS_LNA_EN", "NC", "NC", "NC", "GRFC_14", "GSM_TX2_PHASE_D", "NC", "NC", "RFFE3_DATA", "RFFE3_CLK", "NC", "NC", "RFFE5_DATA", "RFFE5_CLK", "NC", "COEX_UART_TX", "COEX_UART_RX", "RFFE2_DATA", "RFFE2_CLK", "RFFE1_DATA", "RFFE1_CLK";
			phandle = <0x3c>;

			blsp1-spi1-default-state {
				phandle = <0x96>;

				spi-pins {
					pins = "gpio0", "gpio1", "gpio3";
					function = "blsp_spi1";
					drive-strength = <0x0c>;
					bias-disable;
				};

				cs-pins {
					pins = "gpio2";
					function = "gpio";
					drive-strength = <0x10>;
					bias-disable;
					output-high;
				};
			};

			blsp1-spi1-sleep-state {
				pins = "gpio0", "gpio1", "gpio2", "gpio3";
				function = "gpio";
				drive-strength = <0x02>;
				bias-pull-down;
				phandle = <0x97>;
			};

			blsp2-uart2-2pins-state {
				pins = "gpio4", "gpio5";
				function = "blsp_uart8";
				drive-strength = <0x10>;
				bias-disable;
			};

			blsp2-uart2-2pins-sleep-state {
				pins = "gpio4", "gpio5";
				function = "gpio";
				drive-strength = <0x02>;
				bias-disable;
			};

			blsp2-i2c2-state {
				pins = "gpio6", "gpio7";
				function = "blsp_i2c8";
				drive-strength = <0x10>;
				bias-disable;
				phandle = <0x9f>;
			};

			blsp2-i2c2-sleep-state {
				pins = "gpio6", "gpio7";
				function = "gpio";
				drive-strength = <0x02>;
				bias-disable;
				phandle = <0xa0>;
			};

			blsp1-i2c6-state {
				pins = "gpio27", "gpio28";
				function = "blsp_i2c6";
				drive-strength = <0x10>;
				bias-disable;
				phandle = <0x9a>;
			};

			blsp1-i2c6-sleep-state {
				pins = "gpio27", "gpio28";
				function = "gpio";
				drive-strength = <0x02>;
				bias-pull-up;
				phandle = <0x9b>;
			};

			cci0-default-state {
				pins = "gpio17", "gpio18";
				function = "cci_i2c";
				drive-strength = <0x10>;
				bias-disable;
				phandle = <0x59>;
			};

			camera-rear-default-state {

				mclk0-pins {
					pins = "gpio13";
					function = "cam_mclk";
					drive-strength = <0x10>;
					bias-disable;
				};

				rst-pins {
					pins = "gpio25";
					function = "gpio";
					drive-strength = <0x10>;
					bias-disable;
				};

				pwdn-pins {
					pins = "gpio26";
					function = "gpio";
					drive-strength = <0x10>;
					bias-disable;
				};
			};

			cci1-default-state {
				pins = "gpio19", "gpio20";
				function = "cci_i2c";
				drive-strength = <0x10>;
				bias-disable;
				phandle = <0x5a>;
			};

			camera-board-default-state {

				mclk1-pins {
					pins = "gpio14";
					function = "cam_mclk";
					drive-strength = <0x10>;
					bias-disable;
				};

				pwdn-pins {
					pins = "gpio98";
					function = "gpio";
					drive-strength = <0x10>;
					bias-disable;
				};

				rst-pins {
					pins = "gpio104";
					function = "gpio";
					drive-strength = <0x10>;
					bias-disable;
				};
			};

			camera-front-default-state {

				mclk2-pins {
					pins = "gpio15";
					function = "cam_mclk";
					drive-strength = <0x10>;
					bias-disable;
				};

				rst-pins {
					pins = "gpio23";
					function = "gpio";
					drive-strength = <0x10>;
					bias-disable;
				};

				pwdn-pins {
					pins = "gpio133";
					function = "gpio";
					drive-strength = <0x10>;
					bias-disable;
				};
			};

			pcie0-state-on-state {
				phandle = <0x4c>;

				perst-pins {
					pins = "gpio35";
					function = "gpio";
					drive-strength = <0x02>;
					bias-pull-down;
				};

				clkreq-pins {
					pins = "gpio36";
					function = "pci_e0";
					drive-strength = <0x02>;
					bias-pull-up;
				};

				wake-pins {
					pins = "gpio37";
					function = "gpio";
					drive-strength = <0x02>;
					bias-pull-up;
				};
			};

			pcie0-state-off-state {
				phandle = <0x4d>;

				perst-pins {
					pins = "gpio35";
					function = "gpio";
					drive-strength = <0x02>;
					bias-pull-down;
				};

				clkreq-pins {
					pins = "gpio36";
					function = "gpio";
					drive-strength = <0x02>;
					bias-disable;
				};

				wake-pins {
					pins = "gpio37";
					function = "gpio";
					drive-strength = <0x02>;
					bias-disable;
				};
			};

			blsp1-uart2-default-state {
				pins = "gpio41", "gpio42", "gpio43", "gpio44";
				function = "blsp_uart2";
				drive-strength = <0x10>;
				bias-disable;
				phandle = <0x92>;
			};

			blsp1-uart2-sleep-state {
				pins = "gpio41", "gpio42", "gpio43", "gpio44";
				function = "gpio";
				drive-strength = <0x02>;
				bias-disable;
				phandle = <0x93>;
			};

			blsp1-i2c3-default-state {
				pins = "gpio47", "gpio48";
				function = "blsp_i2c3";
				drive-strength = <0x10>;
				bias-disable;
				phandle = <0x98>;
			};

			blsp1-i2c3-sleep-state {
				pins = "gpio47", "gpio48";
				function = "gpio";
				drive-strength = <0x02>;
				bias-disable;
				phandle = <0x99>;
			};

			blsp2-uart3-4pins-state {
				pins = "gpio49", "gpio50", "gpio51", "gpio52";
				function = "blsp_uart9";
				drive-strength = <0x10>;
				bias-disable;
			};

			blsp2-uart3-4pins-sleep-state {
				pins = "gpio49", "gpio50", "gpio51", "gpio52";
				function = "blsp_uart9";
				drive-strength = <0x02>;
				bias-disable;
			};

			blsp2-i2c3-state-state {
				pins = "gpio51", "gpio52";
				function = "blsp_i2c9";
				drive-strength = <0x10>;
				bias-disable;
				phandle = <0xa2>;
			};

			blsp2-i2c3-sleep-state {
				pins = "gpio51", "gpio52";
				function = "gpio";
				drive-strength = <0x02>;
				bias-disable;
				phandle = <0xa3>;
			};

			wcd-intr-default-state {
				pins = "gpio54";
				function = "gpio";
				drive-strength = <0x02>;
				bias-pull-down;
				phandle = <0xb4>;
			};

			blsp2-i2c1-state {
				pins = "gpio55", "gpio56";
				function = "blsp_i2c7";
				drive-strength = <0x10>;
				bias-disable;
				phandle = <0x9c>;
			};

			blsp2-i2c1-sleep-state {
				pins = "gpio55", "gpio56";
				function = "gpio";
				drive-strength = <0x02>;
				bias-disable;
				phandle = <0x9d>;
			};

			blsp2-i2c5-state {
				pins = "gpio60", "gpio61";
				function = "blsp_i2c11";
				drive-strength = <0x02>;
				bias-disable;
				phandle = <0xa6>;
			};

			cdc-reset-active-state {
				pins = "gpio64";
				function = "gpio";
				drive-strength = <0x10>;
				bias-pull-down;
				output-high;
				phandle = <0xb3>;
			};

			cdc-reset-sleep-state {
				pins = "gpio64";
				function = "gpio";
				drive-strength = <0x10>;
				bias-disable;
				output-low;
			};

			blsp2-spi6-default-state {
				phandle = <0xad>;

				spi-pins {
					pins = "gpio85", "gpio86", "gpio88";
					function = "blsp_spi12";
					drive-strength = <0x0c>;
					bias-disable;
				};

				cs-pins {
					pins = "gpio87";
					function = "gpio";
					drive-strength = <0x10>;
					bias-disable;
					output-high;
				};
			};

			blsp2-spi6-sleep-state {
				pins = "gpio85", "gpio86", "gpio87", "gpio88";
				function = "gpio";
				drive-strength = <0x02>;
				bias-pull-down;
				phandle = <0xae>;
			};

			blsp2-i2c6-state {
				pins = "gpio87", "gpio88";
				function = "blsp_i2c12";
				drive-strength = <0x10>;
				bias-disable;
				phandle = <0xa7>;
			};

			blsp2-i2c6-sleep-state {
				pins = "gpio87", "gpio88";
				function = "gpio";
				drive-strength = <0x02>;
				bias-disable;
				phandle = <0xa8>;
			};

			pcie1-on-state {
				phandle = <0x4f>;

				perst-pins {
					pins = "gpio130";
					function = "gpio";
					drive-strength = <0x02>;
					bias-pull-down;
				};

				clkreq-pins {
					pins = "gpio131";
					function = "pci_e1";
					drive-strength = <0x02>;
					bias-pull-up;
				};

				wake-pins {
					pins = "gpio132";
					function = "gpio";
					drive-strength = <0x02>;
					bias-pull-down;
				};
			};

			pcie1-off-state {
				phandle = <0x50>;

				clkreq-pins {
					pins = "gpio131";
					function = "gpio";
					drive-strength = <0x02>;
					bias-disable;
				};

				wake-pins {
					pins = "gpio132";
					function = "gpio";
					drive-strength = <0x02>;
					bias-disable;
				};
			};

			pcie2-on-state {
				phandle = <0x51>;

				perst-pins {
					pins = "gpio114";
					function = "gpio";
					drive-strength = <0x02>;
					bias-pull-down;
				};

				clkreq-pins {
					pins = "gpio115";
					function = "pci_e2";
					drive-strength = <0x02>;
					bias-pull-up;
				};

				wake-pins {
					pins = "gpio116";
					function = "gpio";
					drive-strength = <0x02>;
					bias-pull-down;
				};
			};

			pcie2-off-state {
				phandle = <0x52>;

				clkreq-pins {
					pins = "gpio115";
					function = "gpio";
					drive-strength = <0x02>;
					bias-disable;
				};

				wake-pins {
					pins = "gpio116";
					function = "gpio";
					drive-strength = <0x02>;
					bias-disable;
				};
			};

			sdc1-on-state {
				phandle = <0x8e>;

				clk-pins {
					pins = "sdc1_clk";
					bias-disable;
					drive-strength = <0x10>;
				};

				cmd-pins {
					pins = "sdc1_cmd";
					bias-pull-up;
					drive-strength = <0x0a>;
				};

				data-pins {
					pins = "sdc1_data";
					bias-pull-up;
					drive-strength = <0x0a>;
				};

				rclk-pins {
					pins = "sdc1_rclk";
					bias-pull-down;
				};
			};

			sdc1-off-state {
				phandle = <0x8f>;

				clk-pins {
					pins = "sdc1_clk";
					bias-disable;
					drive-strength = <0x02>;
				};

				cmd-pins {
					pins = "sdc1_cmd";
					bias-pull-up;
					drive-strength = <0x02>;
				};

				data-pins {
					pins = "sdc1_data";
					bias-pull-up;
					drive-strength = <0x02>;
				};

				rclk-pins {
					pins = "sdc1_rclk";
					bias-pull-down;
				};
			};

			sdc2-on-state {
				phandle = <0x90>;

				clk-pins {
					pins = "sdc2_clk";
					bias-disable;
					drive-strength = <0x10>;
				};

				cmd-pins {
					pins = "sdc2_cmd";
					bias-pull-up;
					drive-strength = <0x0a>;
				};

				data-pins {
					pins = "sdc2_data";
					bias-pull-up;
					drive-strength = <0x0a>;
				};
			};

			sdc2-off-state {
				phandle = <0x91>;

				clk-pins {
					pins = "sdc2_clk";
					bias-disable;
					drive-strength = <0x02>;
				};

				cmd-pins {
					pins = "sdc2_cmd";
					bias-pull-up;
					drive-strength = <0x02>;
				};

				data-pins {
					pins = "sdc2_data";
					bias-pull-up;
					drive-strength = <0x02>;
				};
			};

			cam-sensor-rear-default-state {
				pins = "gpio30";
				function = "gpio";
				drive-strength = <0x02>;
				bias-disable;
			};

			cam-sensor-rear-sleep-state {
				pins = "gpio30";
				function = "gpio";
				drive-strength = <0x02>;
				bias-pull-up;
			};

			mclk0-default-state {
				pins = "gpio13";
				function = "cam_mclk";
				drive-strength = <0x02>;
				bias-disable;
			};

			mclk0-sleep-state {
				pins = "gpio13";
				function = "gpio";
				drive-strength = <0x02>;
				bias-pull-down;
			};

			mdss-dsi-default-state {
				pins = "gpio8";
				function = "gpio";
				drive-strength = <0x08>;
				bias-disable;
				phandle = <0x35>;
			};

			mdss-dsi-sleep-state {
				pins = "gpio8";
				function = "gpio";
				drive-strength = <0x02>;
				bias-pull-down;
				phandle = <0x37>;
			};

			mdss-te-default-state {
				pins = "gpio10";
				function = "mdp_vsync";
				drive-strength = <0x02>;
				bias-pull-down;
				phandle = <0x36>;
			};

			mdss-te-sleep-state {
				pins = "gpio10";
				function = "mdp_vsync";
				drive-strength = <0x02>;
				bias-pull-down;
				phandle = <0x38>;
			};

			nfc-default-state {
				pins = "gpio12", "gpio21";
				function = "gpio";
				drive-strength = <0x10>;
				bias-pull-up;
				phandle = <0xa1>;
			};

			vdd-cam-1p1-default-state {
				pins = "gpio86";
				function = "gpio";
				drive-strength = <0x10>;
				bias-disable;
				phandle = <0xd0>;
			};

			touchscreen-default-state {
				pins = "gpio89", "gpio125";
				function = "gpio";
				drive-strength = <0x0a>;
				bias-pull-up;
				phandle = <0xab>;
			};

			touchscreen-sleep-state {
				pins = "gpio89", "gpio125";
				function = "gpio";
				drive-strength = <0x02>;
				bias-disable;
				phandle = <0xac>;
			};

			vibrator-default-state {
				pins = "gpio93";
				function = "gpio";
				drive-strength = <0x08>;
				bias-pull-up;
				phandle = <0xa4>;
			};

			vibrator-sleep-state {
				pins = "gpio93";
				function = "gpio";
				drive-strength = <0x02>;
				bias-disable;
				phandle = <0xa5>;
			};
		};

		sram@290000 {
			compatible = "qcom,rpm-stats";
			reg = <0x290000 0x10000>;
		};

		spmi@400f000 {
			compatible = "qcom,spmi-pmic-arb";
			reg = <0x400f000 0x1000 0x4400000 0x800000 0x4c00000 0x800000 0x5800000 0x200000 0x400a000 0x2100>;
			reg-names = "core", "chnls", "obsrvr", "intr", "cnfg";
			interrupt-names = "periph_irq";
			interrupts = <0x00 0x146 0x04>;
			qcom,ee = <0x00>;
			qcom,channel = <0x00>;
			#address-cells = <0x02>;
			#size-cells = <0x00>;
			interrupt-controller;
			#interrupt-cells = <0x04>;

			pmic@0 {
				compatible = "qcom,pm8994", "qcom,spmi-pmic";
				reg = <0x00 0x00>;
				#address-cells = <0x01>;
				#size-cells = <0x00>;

				rtc@6000 {
					compatible = "qcom,pm8941-rtc";
					reg = <0x6000 0x6100>;
					reg-names = "rtc", "alarm";
					interrupts = <0x00 0x61 0x01 0x01>;
				};

				pon@800 {
					compatible = "qcom,pm8916-pon";
					reg = <0x800>;
					mode-bootloader = <0x02>;
					mode-recovery = <0x01>;

					pwrkey {
						compatible = "qcom,pm8941-pwrkey";
						interrupts = <0x00 0x08 0x00 0x03>;
						debounce = <0x3d09>;
						bias-pull-up;
						linux,code = <0x74>;
					};

					resin {
						compatible = "qcom,pm8941-resin";
						interrupts = <0x00 0x08 0x01 0x03>;
						debounce = <0x3d09>;
						bias-pull-up;
						status = "okay";
						linux,code = <0x72>;
					};
				};

				temp-alarm@2400 {
					compatible = "qcom,spmi-temp-alarm";
					reg = <0x2400>;
					interrupts = <0x00 0x24 0x00 0x01>;
					io-channels = <0x44 0x08>;
					io-channel-names = "thermal";
					#thermal-sensor-cells = <0x00>;
					phandle = <0xcb>;
				};

				adc@3100 {
					compatible = "qcom,spmi-vadc";
					reg = <0x3100>;
					interrupts = <0x00 0x31 0x00 0x01>;
					#address-cells = <0x01>;
					#size-cells = <0x00>;
					#io-channel-cells = <0x01>;
					phandle = <0x44>;

					channel@7 {
						reg = <0x07>;
						qcom,pre-scaling = <0x01 0x03>;
						label = "vph_pwr";
					};

					channel@8 {
						reg = <0x08>;
						label = "die_temp";
					};

					channel@9 {
						reg = <0x09>;
						label = "ref_625mv";
					};

					channel@a {
						reg = <0x0a>;
						label = "ref_1250mv";
					};

					channel@e {
						reg = <0x0e>;
					};

					channel@f {
						reg = <0x0f>;
					};
				};

				gpio@c000 {
					compatible = "qcom,pm8994-gpio", "qcom,spmi-gpio";
					reg = <0xc000>;
					gpio-controller;
					gpio-ranges = <0x45 0x00 0x00 0x16>;
					#gpio-cells = <0x02>;
					interrupt-controller;
					#interrupt-cells = <0x02>;
					gpio-line-names = "NC", "VOL_UP_N", "SPKR_ID", "PWM_HAPTICS", "INFARED_DRV", "NC", "KEYPAD_LED_EN", "WL_EN", "3P3_ENABLE", "FP_ID", "NC", "NC", "NC", "NC", "DIVCLK1_CDC", "DIVCLK2_HAPTICS", "NC", "32KHz_CLK_IN", "BT_EN", "PMIC_SLB", "UIM_BATT_ALARM", "NC";
					phandle = <0x45>;

					irled-default-state {
						pins = "gpio5";
						function = "func1";
						output-low;
						qcom,drive-strength = <0x01>;
						power-source = <0x02>;
						bias-disable;
						phandle = <0xcf>;
					};

					wlan-en-state {
						pins = "gpio8";
						function = "normal";
						output-low;
						qcom,drive-strength = <0x03>;
						power-source = <0x02>;
						bias-disable;
						phandle = <0xd2>;
					};

					rome-enable-state {
						pins = "gpio9";
						function = "normal";
						output-high;
						qcom,drive-strength = <0x03>;
						power-source = <0x00>;
						phandle = <0xd1>;
					};

					divclk1-state {
						pins = "gpio15";
						function = "func1";
						bias-disable;
						power-source = <0x02>;
						qcom,drive-strength = <0x03>;
						phandle = <0xcc>;
					};

					divclk4-state {
						pins = "gpio18";
						function = "func2";
						bias-disable;
						power-source = <0x02>;
						phandle = <0xcd>;
					};

					divclk2-state {
						pins = "gpio16";
						function = "func2";
						bias-disable;
						power-source = <0x02>;
						phandle = <0xd3>;
					};
				};

				mpps@a000 {
					compatible = "qcom,pm8994-mpp", "qcom,spmi-mpp";
					reg = <0xa000>;
					gpio-controller;
					#gpio-cells = <0x02>;
					gpio-ranges = <0x46 0x00 0x00 0x08>;
					interrupt-controller;
					#interrupt-cells = <0x02>;
					gpio-line-names = "NC", "CCI_TIMER1", "PMIC_SLB", "EXT_FET_WLED_PWR_EN_N", "NC", "NC", "NC", "NC";
					phandle = <0x46>;
				};
			};

			pmic@1 {
				compatible = "qcom,pm8994", "qcom,spmi-pmic";
				reg = <0x01 0x00>;
				#address-cells = <0x01>;
				#size-cells = <0x00>;

				pwm {
					compatible = "qcom,pm8994-lpg";
					#address-cells = <0x01>;
					#size-cells = <0x00>;
					#pwm-cells = <0x02>;
					status = "okay";
					qcom,power-source = <0x01>;
					phandle = <0xce>;
				};

				regulators {
					compatible = "qcom,pm8994-regulators";
					qcom,saw-reg = <0x47>;

					s8 {
						qcom,saw-slave;
					};

					s9 {
						qcom,saw-slave;
					};

					s10 {
						qcom,saw-slave;
					};

					s11 {
						qcom,saw-leader;
						regulator-name = "vreg_apc_0p8";
						regulator-min-microvolt = <0x72bf0>;
						regulator-max-microvolt = <0x116520>;
						regulator-max-step-microvolt = <0x249f0>;
						regulator-always-on;
					};
				};
			};

			pmic@2 {
				compatible = "qcom,pmi8994", "qcom,spmi-pmic";
				reg = <0x02 0x00>;
				#address-cells = <0x01>;
				#size-cells = <0x00>;

				charger@1000 {
					compatible = "qcom,pmi8994-smbchg";
					reg = <0x1000>;
					interrupts = <0x02 0x10 0x00 0x03 0x02 0x10 0x01 0x03 0x02 0x10 0x02 0x03 0x02 0x10 0x03 0x03 0x02 0x10 0x04 0x03 0x02 0x10 0x05 0x03 0x02 0x10 0x06 0x01 0x02 0x10 0x07 0x01 0x02 0x12 0x00 0x03 0x02 0x12 0x01 0x03 0x02 0x12 0x02 0x03 0x02 0x12 0x03 0x03 0x02 0x12 0x04 0x03 0x02 0x12 0x05 0x03 0x02 0x12 0x06 0x03 0x02 0x12 0x07 0x03 0x02 0x13 0x00 0x03 0x02 0x13 0x01 0x03 0x02 0x13 0x02 0x03 0x02 0x13 0x03 0x03 0x02 0x13 0x04 0x01 0x02 0x13 0x05 0x01 0x02 0x13 0x06 0x02 0x02 0x14 0x00 0x03 0x02 0x14 0x01 0x03 0x02 0x16 0x00 0x03 0x02 0x16 0x01 0x03 0x02 0x16 0x02 0x03 0x02 0x16 0x03 0x03 0x02 0x16 0x04 0x03 0x02 0x16 0x05 0x03>;
					interrupt-names = "chg-error", "chg-inhibit", "chg-prechg-sft", "chg-complete-chg-sft", "chg-p2f-thr", "chg-rechg-thr", "chg-taper-thr", "chg-tcc-thr", "batt-hot", "batt-warm", "batt-cold", "batt-cool", "batt-ov", "batt-low", "batt-missing", "batt-term-missing", "usbin-uv", "usbin-ov", "usbin-src-det", "otg-fail", "otg-oc", "aicl-done", "usbid-change", "dcin-uv", "dcin-ov", "power-ok", "temp-shutdown", "wdog-timeout", "flash-fail", "otst2", "otst3";
					status = "okay";
					monitored-battery = <0x48>;
					phandle = <0x49>;

					otg-vbus {
						phandle = <0x8a>;
					};
				};

				fuel-gauge@4000 {
					compatible = "qcom,pmi8994-fg";
					reg = <0x4000>;
					interrupts = <0x02 0x40 0x04 0x01 0x02 0x44 0x00 0x03>;
					interrupt-names = "soc-delta", "mem-avail";
					power-supplies = <0x49>;
					status = "okay";
					monitored-battery = <0x48>;
				};

				gpio@c000 {
					compatible = "qcom,pmi8994-gpio", "qcom,spmi-gpio";
					reg = <0xc000>;
					gpio-controller;
					gpio-ranges = <0x4a 0x00 0x00 0x0a>;
					#gpio-cells = <0x02>;
					interrupt-controller;
					#interrupt-cells = <0x02>;
					gpio-line-names = "NC", "SPKR_PA_RST", "NC", "NC", "NC", "NC", "NC", "NC", "NC", "NC";
					phandle = <0x4a>;
				};

				mpps@a000 {
					compatible = "qcom,pmi8994-mpp", "qcom,spmi-mpp";
					reg = <0xa000>;
					gpio-controller;
					gpio-ranges = <0x4b 0x00 0x00 0x04>;
					#gpio-cells = <0x02>;
					interrupt-controller;
					#interrupt-cells = <0x02>;
					phandle = <0x4b>;
				};
			};

			pmic@3 {
				compatible = "qcom,pmi8994", "qcom,spmi-pmic";
				reg = <0x03 0x00>;
				#address-cells = <0x01>;
				#size-cells = <0x00>;

				pwm {
					compatible = "qcom,pmi8994-lpg";
					#address-cells = <0x01>;
					#size-cells = <0x00>;
					#pwm-cells = <0x02>;
					status = "okay";
					qcom,power-source = <0x01>;

					multi-led {
						color = <0x09>;
						function = "status";
						#address-cells = <0x01>;
						#size-cells = <0x00>;

						led@1 {
							reg = <0x01>;
							color = <0x03>;
						};

						led@2 {
							reg = <0x02>;
							color = <0x02>;
						};

						led@3 {
							reg = <0x03>;
							color = <0x01>;
						};
					};
				};

				regulators {
					compatible = "qcom,pmi8994-regulators";

					s2 {
						regulator-name = "vdd_gfx";
						regulator-min-microvolt = <0x61a80>;
						regulator-max-microvolt = <0xf7cd8>;
						regulator-enable-ramp-delay = <0x1f4>;
						phandle = <0x2b>;
					};
				};

				qcom,haptics@c000 {
					compatible = "qcom,pmi8994-haptics", "qcom,spmi-haptics";
					reg = <0xc000 0x100>;
					interrupts = <0x03 0xc0 0x00 0x03 0x03 0xc0 0x01 0x03>;
					interrupt-names = "short", "play";
					qcom,play-mode = <0x01>;
					status = "disabled";
				};

				wled@d800 {
					compatible = "qcom,pmi8994-wled";
					reg = <0xd800 0xd900>;
					interrupts = <0x03 0xd8 0x01 0x01 0x03 0xd8 0x02 0x01>;
					interrupt-names = "ovp", "short";
					label = "backlight";
					qcom,cabc;
					qcom,external-pfet;
					status = "okay";
					phandle = <0x3d>;
				};
			};
		};

		bus@0 {
			power-domains = <0x1c 0x00>;
			compatible = "simple-pm-bus";
			#address-cells = <0x01>;
			#size-cells = <0x01>;
			ranges = <0x00 0x00 0xffffffff>;

			pcie@600000 {
				compatible = "qcom,pcie-msm8996";
				status = "okay";
				power-domains = <0x1c 0x05>;
				bus-range = <0x00 0xff>;
				num-lanes = <0x01>;
				reg = <0x600000 0x2000 0xc000000 0xf1d 0xc000f20 0xa8 0xc100000 0x100000>;
				reg-names = "parf", "dbi", "elbi", "config";
				phys = <0x21>;
				phy-names = "pciephy";
				#address-cells = <0x03>;
				#size-cells = <0x02>;
				ranges = <0x1000000 0x00 0x00 0xc200000 0x00 0x100000 0x2000000 0x00 0xc300000 0xc300000 0x00 0xd00000>;
				device_type = "pci";
				interrupts = <0x00 0x195 0x04 0x00 0x196 0x04 0x00 0x197 0x04 0x00 0x198 0x04 0x00 0x199 0x04 0x00 0x19a 0x04 0x00 0x19b 0x04 0x00 0x19c 0x04>;
				interrupt-names = "msi0", "msi1", "msi2", "msi3", "msi4", "msi5", "msi6", "msi7";
				#interrupt-cells = <0x01>;
				interrupt-map-mask = <0x00 0x00 0x00 0x07>;
				interrupt-map = <0x00 0x00 0x00 0x01 0x01 0x00 0xf4 0x04 0x00 0x00 0x00 0x02 0x01 0x00 0xf5 0x04 0x00 0x00 0x00 0x03 0x01 0x00 0xf7 0x04 0x00 0x00 0x00 0x04 0x01 0x00 0xf8 0x04>;
				pinctrl-names = "default", "sleep";
				pinctrl-0 = <0x4c>;
				pinctrl-1 = <0x4d>;
				linux,pci-domain = <0x00>;
				clocks = <0x1c 0xb4 0x1c 0xb3 0x1c 0xb2 0x1c 0xb1 0x1c 0xb0>;
				clock-names = "pipe", "aux", "cfg", "bus_master", "bus_slave";
				vddpe-3v3-supply = <0x4e>;
				vdda-supply = <0x1d>;
				perst-gpios = <0x3c 0x23 0x01>;
				wake-gpios = <0x3c 0x25 0x00>;

				pcie@0 {
					device_type = "pci";
					reg = <0x00 0x00 0x00 0x00 0x00>;
					bus-range = <0x01 0xff>;
					#address-cells = <0x03>;
					#size-cells = <0x02>;
					ranges;
				};
			};

			pcie@608000 {
				compatible = "qcom,pcie-msm8996";
				power-domains = <0x1c 0x06>;
				bus-range = <0x00 0xff>;
				num-lanes = <0x01>;
				status = "disabled";
				reg = <0x608000 0x2000 0xd000000 0xf1d 0xd000f20 0xa8 0xd100000 0x100000>;
				reg-names = "parf", "dbi", "elbi", "config";
				phys = <0x22>;
				phy-names = "pciephy";
				#address-cells = <0x03>;
				#size-cells = <0x02>;
				ranges = <0x1000000 0x00 0x00 0xd200000 0x00 0x100000 0x2000000 0x00 0xd300000 0xd300000 0x00 0xd00000>;
				device_type = "pci";
				interrupts = <0x00 0x19d 0x04 0x00 0x19e 0x04 0x00 0x19f 0x04 0x00 0x1a0 0x04 0x00 0x1a1 0x04 0x00 0x1a2 0x04 0x00 0x1a3 0x04 0x00 0x1a4 0x04>;
				interrupt-names = "msi0", "msi1", "msi2", "msi3", "msi4", "msi5", "msi6", "msi7";
				#interrupt-cells = <0x01>;
				interrupt-map-mask = <0x00 0x00 0x00 0x07>;
				interrupt-map = <0x00 0x00 0x00 0x01 0x01 0x00 0x110 0x04 0x00 0x00 0x00 0x02 0x01 0x00 0x111 0x04 0x00 0x00 0x00 0x03 0x01 0x00 0x112 0x04 0x00 0x00 0x00 0x04 0x01 0x00 0x113 0x04>;
				pinctrl-names = "default", "sleep";
				pinctrl-0 = <0x4f>;
				pinctrl-1 = <0x50>;
				linux,pci-domain = <0x01>;
				clocks = <0x1c 0xb9 0x1c 0xb8 0x1c 0xb7 0x1c 0xb6 0x1c 0xb5>;
				clock-names = "pipe", "aux", "cfg", "bus_master", "bus_slave";

				pcie@0 {
					device_type = "pci";
					reg = <0x00 0x00 0x00 0x00 0x00>;
					bus-range = <0x01 0xff>;
					#address-cells = <0x03>;
					#size-cells = <0x02>;
					ranges;
				};
			};

			pcie@610000 {
				compatible = "qcom,pcie-msm8996";
				power-domains = <0x1c 0x07>;
				bus-range = <0x00 0xff>;
				num-lanes = <0x01>;
				status = "disabled";
				reg = <0x610000 0x2000 0xe000000 0xf1d 0xe000f20 0xa8 0xe100000 0x100000>;
				reg-names = "parf", "dbi", "elbi", "config";
				phys = <0x23>;
				phy-names = "pciephy";
				#address-cells = <0x03>;
				#size-cells = <0x02>;
				ranges = <0x1000000 0x00 0x00 0xe200000 0x00 0x100000 0x2000000 0x00 0xe300000 0xe300000 0x00 0x1d00000>;
				device_type = "pci";
				interrupts = <0x00 0x1a5 0x04 0x00 0x1a6 0x04 0x00 0x1a7 0x04 0x00 0x1a8 0x04 0x00 0x1a9 0x04 0x00 0x1aa 0x04 0x00 0x1ab 0x04 0x00 0x1ac 0x04>;
				interrupt-names = "msi0", "msi1", "msi2", "msi3", "msi4", "msi5", "msi6", "msi7";
				#interrupt-cells = <0x01>;
				interrupt-map-mask = <0x00 0x00 0x00 0x07>;
				interrupt-map = <0x00 0x00 0x00 0x01 0x01 0x00 0x8e 0x04 0x00 0x00 0x00 0x02 0x01 0x00 0x8f 0x04 0x00 0x00 0x00 0x03 0x01 0x00 0x90 0x04 0x00 0x00 0x00 0x04 0x01 0x00 0x91 0x04>;
				pinctrl-names = "default", "sleep";
				pinctrl-0 = <0x51>;
				pinctrl-1 = <0x52>;
				linux,pci-domain = <0x02>;
				clocks = <0x1c 0xbe 0x1c 0xbd 0x1c 0xbc 0x1c 0xbb 0x1c 0xba>;
				clock-names = "pipe", "aux", "cfg", "bus_master", "bus_slave";

				pcie@0 {
					device_type = "pci";
					reg = <0x00 0x00 0x00 0x00 0x00>;
					bus-range = <0x01 0xff>;
					#address-cells = <0x03>;
					#size-cells = <0x02>;
					ranges;
				};
			};
		};

		ufshc@624000 {
			compatible = "qcom,msm8996-ufshc", "qcom,ufshc", "jedec,ufs-2.0";
			reg = <0x624000 0x2500>;
			interrupts = <0x00 0x109 0x04>;
			phys = <0x25>;
			phy-names = "ufsphy";
			power-domains = <0x1c 0x08>;
			clock-names = "core_clk", "bus_clk", "bus_aggr_clk", "iface_clk", "core_clk_unipro", "core_clk_ice", "ref_clk", "tx_lane0_sync_clk", "rx_lane0_sync_clk";
			clocks = <0x1c 0xc1 0x1c 0x52 0x1c 0xd1 0x1c 0xc2 0x1c 0xc8 0x1c 0xc9 0x1f 0x4a 0x1c 0xc5 0x1c 0xc6>;
			freq-table-hz = <0x5f5e100 0xbebc200 0x00 0x00 0x00 0x00 0x00 0x00 0x47868c0 0x8f0d180 0x8f0d180 0x11e1a300 0x00 0x00 0x00 0x00 0x00 0x00>;
			interconnects = <0x53 0x02 0x2f 0x04 0x2f 0x00 0x54 0x1d>;
			interconnect-names = "ufs-ddr", "cpu-ufs";
			lanes-per-direction = <0x01>;
			#reset-cells = <0x01>;
			status = "okay";
			vcc-supply = <0x55>;
			vccq-supply = <0x56>;
			vccq2-supply = <0x19>;
			vdd-hba-supply = <0x56>;
			vcc-max-microamp = <0x927c0>;
			vccq-max-microamp = <0x6ddd0>;
			vccq2-max-microamp = <0x6ddd0>;
			phandle = <0x57>;
		};

		phy@627000 {
			compatible = "qcom,msm8996-qmp-ufs-phy";
			reg = <0x627000 0x1000>;
			clocks = <0x1f 0x4a 0x1c 0xd7>;
			clock-names = "ref", "qref";
			resets = <0x57 0x00>;
			reset-names = "ufsphy";
			#clock-cells = <0x01>;
			#phy-cells = <0x00>;
			status = "okay";
			vdda-phy-supply = <0x1d>;
			vdda-pll-supply = <0x1e>;
			phandle = <0x25>;
		};

		camss@a34000 {
			compatible = "qcom,msm8996-camss";
			reg = <0xa34000 0x1000 0xa00030 0x04 0xa35000 0x1000 0xa00038 0x04 0xa36000 0x1000 0xa00040 0x04 0xa30000 0x100 0xa30400 0x100 0xa30800 0x100 0xa30c00 0x100 0xa31000 0x500 0xa00020 0x10 0xa10000 0x1000 0xa14000 0x1000>;
			reg-names = "csiphy0", "csiphy0_clk_mux", "csiphy1", "csiphy1_clk_mux", "csiphy2", "csiphy2_clk_mux", "csid0", "csid1", "csid2", "csid3", "ispif", "csi_clk_mux", "vfe0", "vfe1";
			interrupts = <0x00 0x4e 0x01 0x00 0x4f 0x01 0x00 0x50 0x01 0x00 0x128 0x01 0x00 0x129 0x01 0x00 0x12a 0x01 0x00 0x12b 0x01 0x00 0x135 0x01 0x00 0x13a 0x01 0x00 0x13b 0x01>;
			interrupt-names = "csiphy0", "csiphy1", "csiphy2", "csid0", "csid1", "csid2", "csid3", "ispif", "vfe0", "vfe1";
			power-domains = <0x27 0x08 0x27 0x09 0x27 0x07>;
			power-domain-names = "vfe0", "vfe1", "camss";
			clocks = <0x27 0x81 0x27 0xb9 0x27 0x8c 0x27 0x8d 0x27 0x8e 0x27 0xa6 0x27 0xa5 0x27 0xa7 0x27 0xa9 0x27 0xa8 0x27 0xab 0x27 0xaa 0x27 0xac 0x27 0xae 0x27 0xad 0x27 0xb0 0x27 0xaf 0x27 0xb1 0x27 0xb3 0x27 0xb2 0x27 0xb5 0x27 0xb4 0x27 0xb6 0x27 0xb8 0x27 0xb7 0x27 0x82 0x27 0x99 0x27 0x9f 0x27 0x9b 0x27 0x9a 0x27 0x9c 0x27 0xa0 0x27 0x9e 0x27 0x9d 0x27 0x97 0x27 0x98>;
			clock-names = "top_ahb", "ispif_ahb", "csiphy0_timer", "csiphy1_timer", "csiphy2_timer", "csi0_ahb", "csi0", "csi0_phy", "csi0_pix", "csi0_rdi", "csi1_ahb", "csi1", "csi1_phy", "csi1_pix", "csi1_rdi", "csi2_ahb", "csi2", "csi2_phy", "csi2_pix", "csi2_rdi", "csi3_ahb", "csi3", "csi3_phy", "csi3_pix", "csi3_rdi", "ahb", "vfe0", "csi_vfe0", "vfe0_ahb", "vfe0_stream", "vfe1", "csi_vfe1", "vfe1_ahb", "vfe1_stream", "vfe_ahb", "vfe_axi";
			iommus = <0x58 0x00 0x58 0x01 0x58 0x02 0x58 0x03>;
			status = "disabled";

			ports {
				#address-cells = <0x01>;
				#size-cells = <0x00>;
			};
		};

		cci@a0c000 {
			compatible = "qcom,msm8996-cci";
			#address-cells = <0x01>;
			#size-cells = <0x00>;
			reg = <0xa0c000 0x1000>;
			interrupts = <0x00 0x127 0x01>;
			power-domains = <0x27 0x07>;
			clocks = <0x27 0x81 0x27 0x8b 0x27 0x8a 0x27 0x82>;
			clock-names = "camss_top_ahb", "cci_ahb", "cci", "camss_ahb";
			assigned-clocks = <0x27 0x8b 0x27 0x8a>;
			assigned-clock-rates = <0x4c4b400 0x23c3460>;
			pinctrl-names = "default";
			pinctrl-0 = <0x59 0x5a>;
			status = "disabled";

			i2c-bus@0 {
				reg = <0x00>;
				clock-frequency = <0x61a80>;
				#address-cells = <0x01>;
				#size-cells = <0x00>;
			};

			i2c-bus@1 {
				reg = <0x01>;
				clock-frequency = <0x61a80>;
				#address-cells = <0x01>;
				#size-cells = <0x00>;
			};
		};

		iommu@b40000 {
			compatible = "qcom,msm8996-smmu-v2", "qcom,adreno-smmu", "qcom,smmu-v2";
			reg = <0xb40000 0x10000>;
			#global-interrupts = <0x01>;
			interrupts = <0x00 0x14e 0x04 0x00 0x149 0x04 0x00 0x14a 0x04>;
			#iommu-cells = <0x01>;
			clocks = <0x1c 0x5a 0x27 0x68>;
			clock-names = "bus", "iface";
			power-domains = <0x27 0x03>;
			phandle = <0x41>;
		};

		video-codec@c00000 {
			compatible = "qcom,msm8996-venus";
			reg = <0xc00000 0xff000>;
			interrupts = <0x00 0x11f 0x04>;
			power-domains = <0x27 0x04>;
			clocks = <0x27 0x6e 0x27 0x71 0x27 0x6f 0x27 0x70>;
			clock-names = "core", "iface", "bus", "mbus";
			interconnects = <0x2e 0x06 0x2f 0x04 0x2f 0x00 0x2e 0x12>;
			interconnect-names = "video-mem", "cpu-cfg";
			iommus = <0x5b 0x00 0x5b 0x01 0x5b 0x0a 0x5b 0x07 0x5b 0x0e 0x5b 0x0f 0x5b 0x08 0x5b 0x09 0x5b 0x0b 0x5b 0x0c 0x5b 0x0d 0x5b 0x10 0x5b 0x11 0x5b 0x21 0x5b 0x28 0x5b 0x29 0x5b 0x2b 0x5b 0x2c 0x5b 0x2d 0x5b 0x31>;
			memory-region = <0x5c>;
			status = "okay";
			firmware-name = "qcom/msm8996/gemini/venus.mbn";

			video-decoder {
				compatible = "venus-decoder";
				clocks = <0x27 0x72>;
				clock-names = "core";
				power-domains = <0x27 0x05>;
			};

			video-encoder {
				compatible = "venus-encoder";
				clocks = <0x27 0x73>;
				clock-names = "core";
				power-domains = <0x27 0x06>;
			};
		};

		iommu@d00000 {
			compatible = "qcom,msm8996-smmu-v2", "qcom,smmu-v2";
			reg = <0xd00000 0x10000>;
			#global-interrupts = <0x01>;
			interrupts = <0x00 0x49 0x04 0x00 0x140 0x04 0x00 0x141 0x04>;
			#iommu-cells = <0x01>;
			clocks = <0x27 0x5c 0x27 0x5b>;
			clock-names = "bus", "iface";
			power-domains = <0x27 0x0d>;
			phandle = <0x2d>;
		};

		iommu@d40000 {
			compatible = "qcom,msm8996-smmu-v2", "qcom,smmu-v2";
			reg = <0xd40000 0x20000>;
			#global-interrupts = <0x01>;
			interrupts = <0x00 0x11e 0x04 0x00 0x14f 0x04 0x00 0x150 0x04 0x00 0x151 0x04 0x00 0x152 0x04 0x00 0x153 0x04 0x00 0x154 0x04 0x00 0x155 0x04>;
			power-domains = <0x27 0x00>;
			clocks = <0x27 0x63 0x27 0x62>;
			clock-names = "bus", "iface";
			#iommu-cells = <0x01>;
			status = "okay";
			phandle = <0x5b>;
		};

		iommu@da0000 {
			compatible = "qcom,msm8996-smmu-v2", "qcom,smmu-v2";
			reg = <0xda0000 0x10000>;
			#global-interrupts = <0x01>;
			interrupts = <0x00 0x4c 0x04 0x00 0x157 0x04 0x00 0x158 0x04>;
			power-domains = <0x27 0x02>;
			clocks = <0x27 0x4f 0x27 0x4e>;
			clock-names = "bus", "iface";
			#iommu-cells = <0x01>;
			phandle = <0x58>;
		};

		iommu@1600000 {
			compatible = "qcom,msm8996-smmu-v2", "qcom,smmu-v2";
			reg = <0x1600000 0x20000>;
			#iommu-cells = <0x01>;
			power-domains = <0x1c 0x03>;
			#global-interrupts = <0x01>;
			interrupts = <0x00 0x194 0x04 0x00 0xe2 0x04 0x00 0x189 0x04 0x00 0x18a 0x04 0x00 0x18b 0x04 0x00 0x18c 0x04 0x00 0x18d 0x04 0x00 0x18e 0x04 0x00 0x18f 0x04 0x00 0x190 0x04 0x00 0x191 0x04 0x00 0x192 0x04 0x00 0x193 0x04>;
			clocks = <0x1c 0xdc 0x1c 0xdb>;
			clock-names = "bus", "iface";
			phandle = <0xb9>;
		};

		remoteproc@1c00000 {
			compatible = "qcom,msm8996-slpi-pil";
			reg = <0x1c00000 0x4000>;
			interrupts-extended = <0x01 0x00 0x186 0x01 0x5d 0x00 0x01 0x5d 0x01 0x01 0x5d 0x02 0x01 0x5d 0x03 0x01>;
			interrupt-names = "wdog", "fatal", "ready", "handover", "stop-ack";
			clocks = <0x12>;
			clock-names = "xo";
			memory-region = <0x5e>;
			qcom,smem-states = <0x5f 0x00>;
			qcom,smem-state-names = "stop";
			power-domains = <0x60 0x05>;
			power-domain-names = "ssc_cx";
			status = "okay";
			px-supply = <0x61>;
			firmware-name = "qcom/msm8996/gemini/slpi.mbn";

			glink-edge {
				interrupts = <0x00 0xb3 0x01>;
				label = "dsps";
				qcom,remote-pid = <0x03>;
				mboxes = <0x11 0x1b>;
			};

			smd-edge {
				interrupts = <0x00 0xb0 0x01>;
				label = "dsps";
				mboxes = <0x11 0x19>;
				qcom,smd-edge = <0x03>;
				qcom,remote-pid = <0x03>;
			};
		};

		remoteproc@2080000 {
			compatible = "qcom,msm8996-mss-pil";
			reg = <0x2080000 0x100 0x2180000 0x20>;
			reg-names = "qdsp6", "rmb";
			interrupts-extended = <0x01 0x00 0x1c0 0x01 0x62 0x00 0x01 0x62 0x01 0x01 0x62 0x02 0x01 0x62 0x03 0x01 0x62 0x07 0x01>;
			interrupt-names = "wdog", "fatal", "ready", "handover", "stop-ack", "shutdown-ack";
			clocks = <0x1c 0xde 0x1c 0xdf 0x1c 0x9d 0x12 0x1c 0xe5 0x1c 0xe0 0x1c 0xe1 0x1f 0x08>;
			clock-names = "iface", "bus", "mem", "xo", "gpll0_mss", "snoc_axi", "mnoc_axi", "qdss";
			resets = <0x1c 0x69>;
			reset-names = "mss_restart";
			power-domains = <0x60 0x00 0x60 0x03>;
			power-domain-names = "cx", "mx";
			qcom,smem-states = <0x63 0x00>;
			qcom,smem-state-names = "stop";
			qcom,halt-regs = <0x64 0x3000 0x5000 0x4000>;
			status = "okay";
			pll-supply = <0x1e>;
			firmware-name = "qcom/msm8996/gemini/mba.mbn", "qcom/msm8996/gemini/modem.mbn";

			mba {
				memory-region = <0x65>;
			};

			mpss {
				memory-region = <0x66>;
			};

			metadata {
				memory-region = <0x67>;
			};

			glink-edge {
				interrupts = <0x00 0x1c4 0x01>;
				label = "modem";
				qcom,remote-pid = <0x01>;
				mboxes = <0x11 0x0f>;
			};

			smd-edge {
				interrupts = <0x00 0x1c1 0x01>;
				label = "mpss";
				mboxes = <0x11 0x0c>;
				qcom,smd-edge = <0x00>;
				qcom,remote-pid = <0x01>;
			};
		};

		stm@3002000 {
			compatible = "arm,coresight-stm", "arm,primecell";
			reg = <0x3002000 0x1000 0x8280000 0x180000>;
			reg-names = "stm-base", "stm-stimulus-base";
			clocks = <0x1f 0x08 0x1f 0x09>;
			clock-names = "apb_pclk", "atclk";

			out-ports {

				port {

					endpoint {
						remote-endpoint = <0x68>;
						phandle = <0x6a>;
					};
				};
			};
		};

		tpiu@3020000 {
			compatible = "arm,coresight-tpiu", "arm,primecell";
			reg = <0x3020000 0x1000>;
			clocks = <0x1f 0x08 0x1f 0x09>;
			clock-names = "apb_pclk", "atclk";

			in-ports {

				port {

					endpoint {
						remote-endpoint = <0x69>;
						phandle = <0x76>;
					};
				};
			};
		};

		funnel@3021000 {
			compatible = "arm,coresight-dynamic-funnel", "arm,primecell";
			reg = <0x3021000 0x1000>;
			clocks = <0x1f 0x08 0x1f 0x09>;
			clock-names = "apb_pclk", "atclk";

			in-ports {
				#address-cells = <0x01>;
				#size-cells = <0x00>;

				port@7 {
					reg = <0x07>;

					endpoint {
						remote-endpoint = <0x6a>;
						phandle = <0x68>;
					};
				};
			};

			out-ports {

				port {

					endpoint {
						remote-endpoint = <0x6b>;
						phandle = <0x70>;
					};
				};
			};
		};

		funnel@3022000 {
			compatible = "arm,coresight-dynamic-funnel", "arm,primecell";
			reg = <0x3022000 0x1000>;
			clocks = <0x1f 0x08 0x1f 0x09>;
			clock-names = "apb_pclk", "atclk";

			in-ports {
				#address-cells = <0x01>;
				#size-cells = <0x00>;

				port@6 {
					reg = <0x06>;

					endpoint {
						remote-endpoint = <0x6c>;
						phandle = <0x86>;
					};
				};
			};

			out-ports {

				port {

					endpoint {
						remote-endpoint = <0x6d>;
						phandle = <0x71>;
					};
				};
			};
		};

		funnel@3023000 {
			compatible = "arm,coresight-dynamic-funnel", "arm,primecell";
			reg = <0x3023000 0x1000>;
			clocks = <0x1f 0x08 0x1f 0x09>;
			clock-names = "apb_pclk", "atclk";

			in-ports {

				port {

					endpoint {
						remote-endpoint = <0x6e>;
						phandle = <0x0f>;
					};
				};
			};

			out-ports {

				port {

					endpoint {
						remote-endpoint = <0x6f>;
						phandle = <0x72>;
					};
				};
			};
		};

		funnel@3025000 {
			compatible = "arm,coresight-dynamic-funnel", "arm,primecell";
			reg = <0x3025000 0x1000>;
			clocks = <0x1f 0x08 0x1f 0x09>;
			clock-names = "apb_pclk", "atclk";

			in-ports {
				#address-cells = <0x01>;
				#size-cells = <0x00>;

				port@0 {
					reg = <0x00>;

					endpoint {
						remote-endpoint = <0x70>;
						phandle = <0x6b>;
					};
				};

				port@1 {
					reg = <0x01>;

					endpoint {
						remote-endpoint = <0x71>;
						phandle = <0x6d>;
					};
				};

				port@2 {
					reg = <0x02>;

					endpoint {
						remote-endpoint = <0x72>;
						phandle = <0x6f>;
					};
				};
			};

			out-ports {

				port {

					endpoint {
						remote-endpoint = <0x73>;
						phandle = <0x77>;
					};
				};
			};
		};

		replicator@3026000 {
			compatible = "arm,coresight-dynamic-replicator", "arm,primecell";
			reg = <0x3026000 0x1000>;
			clocks = <0x1f 0x08 0x1f 0x09>;
			clock-names = "apb_pclk", "atclk";

			in-ports {

				port {

					endpoint {
						remote-endpoint = <0x74>;
						phandle = <0x78>;
					};
				};
			};

			out-ports {
				#address-cells = <0x01>;
				#size-cells = <0x00>;

				port@0 {
					reg = <0x00>;

					endpoint {
						remote-endpoint = <0x75>;
						phandle = <0x79>;
					};
				};

				port@1 {
					reg = <0x01>;

					endpoint {
						remote-endpoint = <0x76>;
						phandle = <0x69>;
					};
				};
			};
		};

		etf@3027000 {
			compatible = "arm,coresight-tmc", "arm,primecell";
			reg = <0x3027000 0x1000>;
			clocks = <0x1f 0x08 0x1f 0x09>;
			clock-names = "apb_pclk", "atclk";

			in-ports {

				port {

					endpoint {
						remote-endpoint = <0x77>;
						phandle = <0x73>;
					};
				};
			};

			out-ports {

				port {

					endpoint {
						remote-endpoint = <0x78>;
						phandle = <0x74>;
					};
				};
			};
		};

		etr@3028000 {
			compatible = "arm,coresight-tmc", "arm,primecell";
			reg = <0x3028000 0x1000>;
			clocks = <0x1f 0x08 0x1f 0x09>;
			clock-names = "apb_pclk", "atclk";
			arm,scatter-gather;

			in-ports {

				port {

					endpoint {
						remote-endpoint = <0x79>;
						phandle = <0x75>;
					};
				};
			};
		};

		debug@3810000 {
			compatible = "arm,coresight-cpu-debug", "arm,primecell";
			reg = <0x3810000 0x1000>;
			clocks = <0x1f 0x08>;
			clock-names = "apb_pclk";
			cpu = <0x09>;
		};

		etm@3840000 {
			compatible = "arm,coresight-etm4x", "arm,primecell";
			reg = <0x3840000 0x1000>;
			clocks = <0x1f 0x08 0x1f 0x09>;
			clock-names = "apb_pclk", "atclk";
			cpu = <0x09>;

			out-ports {

				port {

					endpoint {
						remote-endpoint = <0x7a>;
						phandle = <0x7c>;
					};
				};
			};
		};

		debug@3910000 {
			compatible = "arm,coresight-cpu-debug", "arm,primecell";
			reg = <0x3910000 0x1000>;
			clocks = <0x1f 0x08>;
			clock-names = "apb_pclk";
			cpu = <0x0a>;
		};

		etm@3940000 {
			compatible = "arm,coresight-etm4x", "arm,primecell";
			reg = <0x3940000 0x1000>;
			clocks = <0x1f 0x08 0x1f 0x09>;
			clock-names = "apb_pclk", "atclk";
			cpu = <0x0a>;

			out-ports {

				port {

					endpoint {
						remote-endpoint = <0x7b>;
						phandle = <0x7d>;
					};
				};
			};
		};

		funnel@39b0000 {
			compatible = "arm,coresight-dynamic-funnel", "arm,primecell";
			reg = <0x39b0000 0x1000>;
			clocks = <0x1f 0x08 0x1f 0x09>;
			clock-names = "apb_pclk", "atclk";

			in-ports {
				#address-cells = <0x01>;
				#size-cells = <0x00>;

				port@0 {
					reg = <0x00>;

					endpoint {
						remote-endpoint = <0x7c>;
						phandle = <0x7a>;
					};
				};

				port@1 {
					reg = <0x01>;

					endpoint {
						remote-endpoint = <0x7d>;
						phandle = <0x7b>;
					};
				};
			};

			out-ports {

				port {

					endpoint {
						remote-endpoint = <0x7e>;
						phandle = <0x84>;
					};
				};
			};
		};

		debug@3a10000 {
			compatible = "arm,coresight-cpu-debug", "arm,primecell";
			reg = <0x3a10000 0x1000>;
			clocks = <0x1f 0x08>;
			clock-names = "apb_pclk";
			cpu = <0x0b>;
		};

		etm@3a40000 {
			compatible = "arm,coresight-etm4x", "arm,primecell";
			reg = <0x3a40000 0x1000>;
			clocks = <0x1f 0x08 0x1f 0x09>;
			clock-names = "apb_pclk", "atclk";
			cpu = <0x0b>;

			out-ports {

				port {

					endpoint {
						remote-endpoint = <0x7f>;
						phandle = <0x81>;
					};
				};
			};
		};

		debug@3b10000 {
			compatible = "arm,coresight-cpu-debug", "arm,primecell";
			reg = <0x3b10000 0x1000>;
			clocks = <0x1f 0x08>;
			clock-names = "apb_pclk";
			cpu = <0x0c>;
		};

		etm@3b40000 {
			compatible = "arm,coresight-etm4x", "arm,primecell";
			reg = <0x3b40000 0x1000>;
			clocks = <0x1f 0x08 0x1f 0x09>;
			clock-names = "apb_pclk", "atclk";
			cpu = <0x0c>;

			out-ports {

				port {

					endpoint {
						remote-endpoint = <0x80>;
						phandle = <0x82>;
					};
				};
			};
		};

		funnel@3bb0000 {
			compatible = "arm,coresight-dynamic-funnel", "arm,primecell";
			reg = <0x3bb0000 0x1000>;
			clocks = <0x1f 0x08 0x1f 0x09>;
			clock-names = "apb_pclk", "atclk";

			in-ports {
				#address-cells = <0x01>;
				#size-cells = <0x00>;

				port@0 {
					reg = <0x00>;

					endpoint {
						remote-endpoint = <0x81>;
						phandle = <0x7f>;
					};
				};

				port@1 {
					reg = <0x01>;

					endpoint {
						remote-endpoint = <0x82>;
						phandle = <0x80>;
					};
				};
			};

			out-ports {

				port {

					endpoint {
						remote-endpoint = <0x83>;
						phandle = <0x85>;
					};
				};
			};
		};

		funnel@3bc0000 {
			compatible = "arm,coresight-dynamic-funnel", "arm,primecell";
			reg = <0x3bc0000 0x1000>;
			clocks = <0x1f 0x08 0x1f 0x09>;
			clock-names = "apb_pclk", "atclk";

			in-ports {
				#address-cells = <0x01>;
				#size-cells = <0x00>;

				port@0 {
					reg = <0x00>;

					endpoint {
						remote-endpoint = <0x84>;
						phandle = <0x7e>;
					};
				};

				port@1 {
					reg = <0x01>;

					endpoint {
						remote-endpoint = <0x85>;
						phandle = <0x83>;
					};
				};
			};

			out-ports {

				port {

					endpoint {
						remote-endpoint = <0x86>;
						phandle = <0x6c>;
					};
				};
			};
		};

		clock-controller@6400000 {
			compatible = "qcom,msm8996-apcc";
			reg = <0x6400000 0x90000>;
			clock-names = "xo", "sys_apcs_aux";
			clocks = <0x1f 0x01 0x11>;
			#clock-cells = <0x01>;
			phandle = <0x03>;
		};

		usb@6af8800 {
			compatible = "qcom,msm8996-dwc3", "qcom,dwc3";
			reg = <0x6af8800 0x400>;
			#address-cells = <0x01>;
			#size-cells = <0x01>;
			ranges;
			interrupts = <0x00 0xb4 0x04 0x00 0x15b 0x04 0x00 0x85 0x04 0x00 0xf3 0x04>;
			interrupt-names = "pwr_event", "qusb2_phy", "hs_phy_irq", "ss_phy_irq";
			clocks = <0x1c 0x51 0x1c 0x5b 0x1c 0xd2 0x1c 0x5c 0x1c 0x5d>;
			clock-names = "cfg_noc", "core", "iface", "sleep", "mock_utmi";
			assigned-clocks = <0x1c 0x5d 0x1c 0x5b>;
			assigned-clock-rates = <0x124f800 0x7270e00>;
			interconnects = <0x53 0x00 0x2f 0x04 0x2f 0x00 0x87 0x0e>;
			interconnect-names = "usb-ddr", "apps-usb";
			power-domains = <0x1c 0x04>;
			status = "okay";
			extcon = <0x88>;
			qcom,select-utmi-as-pipe-clk;

			usb@6a00000 {
				compatible = "snps,dwc3";
				reg = <0x6a00000 0xcc00>;
				interrupts = <0x00 0x83 0x04>;
				phys = <0x89>;
				phy-names = "usb2-phy";
				snps,hird-threshold = [00];
				snps,dis_u2_susphy_quirk;
				snps,dis_enblslpm_quirk;
				snps,is-utmi-l1-suspend;
				snps,parkmode-disable-ss-quirk;
				tx-fifo-resize;
				extcon = <0x88>;
				vbus-supply = <0x8a>;
				usb-psy-name = "qcom-smbchg-usb";
				maximum-speed = "high-speed";
				snps,usb2-gadget-lpm-disable;
			};
		};

		phy@7410000 {
			compatible = "qcom,msm8996-qmp-usb3-phy";
			reg = <0x7410000 0x1000>;
			clocks = <0x1c 0x5e 0x1c 0xd5 0x1c 0x63 0x1c 0x5f>;
			clock-names = "aux", "ref", "cfg_ahb", "pipe";
			clock-output-names = "usb3_phy_pipe_clk_src";
			#clock-cells = <0x00>;
			#phy-cells = <0x00>;
			resets = <0x1c 0x67 0x1c 0x68>;
			reset-names = "phy", "phy_phy";
			status = "disabled";
			phandle = <0x24>;
		};

		phy@7411000 {
			compatible = "qcom,msm8996-qusb2-phy";
			reg = <0x7411000 0x180>;
			#phy-cells = <0x00>;
			clocks = <0x1c 0x63 0x1c 0xda>;
			clock-names = "cfg_ahb", "ref";
			resets = <0x1c 0x09>;
			nvmem-cells = <0x8b>;
			status = "okay";
			vdda-pll-supply = <0x1e>;
			vdda-phy-dpdm-supply = <0x8c>;
			phandle = <0x89>;
		};

		phy@7412000 {
			compatible = "qcom,msm8996-qusb2-phy";
			reg = <0x7412000 0x180>;
			#phy-cells = <0x00>;
			clocks = <0x1c 0x63 0x1c 0xd9>;
			clock-names = "cfg_ahb", "ref";
			resets = <0x1c 0x0a>;
			nvmem-cells = <0x8d>;
			status = "disabled";
			phandle = <0xb0>;
		};

		mmc@7464900 {
			compatible = "qcom,msm8996-sdhci", "qcom,sdhci-msm-v4";
			reg = <0x7464900 0x11c 0x7464000 0x800>;
			reg-names = "hc", "core";
			interrupts = <0x00 0x8d 0x04 0x00 0x86 0x04>;
			interrupt-names = "hc_irq", "pwr_irq";
			clock-names = "iface", "core", "xo";
			clocks = <0x1c 0x65 0x1c 0x64 0x1f 0x00>;
			resets = <0x1c 0x0c>;
			pinctrl-names = "default", "sleep";
			pinctrl-0 = <0x8e>;
			pinctrl-1 = <0x8f>;
			bus-width = <0x08>;
			non-removable;
			status = "disabled";
		};

		mmc@74a4900 {
			compatible = "qcom,msm8996-sdhci", "qcom,sdhci-msm-v4";
			reg = <0x74a4900 0x314 0x74a4000 0x800>;
			reg-names = "hc", "core";
			interrupts = <0x00 0x7d 0x04 0x00 0xdd 0x04>;
			interrupt-names = "hc_irq", "pwr_irq";
			clock-names = "iface", "core", "xo";
			clocks = <0x1c 0x68 0x1c 0x67 0x1f 0x00>;
			resets = <0x1c 0x0d>;
			pinctrl-names = "default", "sleep";
			pinctrl-0 = <0x90>;
			pinctrl-1 = <0x91>;
			bus-width = <0x04>;
			status = "disabled";
		};

		dma-controller@7544000 {
			compatible = "qcom,bam-v1.7.0";
			reg = <0x7544000 0x2b000>;
			interrupts = <0x00 0xee 0x04>;
			clocks = <0x1c 0x6d>;
			clock-names = "bam_clk";
			qcom,controlled-remotely;
			#dma-cells = <0x01>;
			qcom,ee = <0x00>;
			phandle = <0x94>;
		};

		serial@7570000 {
			compatible = "qcom,msm-uartdm-v1.4", "qcom,msm-uartdm";
			reg = <0x7570000 0x1000>;
			interrupts = <0x00 0x6c 0x04>;
			clocks = <0x1c 0x74 0x1c 0x6d>;
			clock-names = "core", "iface";
			pinctrl-names = "default", "sleep";
			pinctrl-0 = <0x92>;
			pinctrl-1 = <0x93>;
			dmas = <0x94 0x02 0x94 0x03>;
			dma-names = "tx", "rx";
			status = "okay";
			label = "QCA_UART";

			bluetooth {
				compatible = "qcom,qca6174-bt";
				enable-gpios = <0x45 0x13 0x00>;
				clocks = <0x95>;
			};
		};

		spi@7575000 {
			compatible = "qcom,spi-qup-v2.2.1";
			reg = <0x7575000 0x600>;
			interrupts = <0x00 0x5f 0x04>;
			clocks = <0x1c 0x6f 0x1c 0x6d>;
			clock-names = "core", "iface";
			pinctrl-names = "default", "sleep";
			pinctrl-0 = <0x96>;
			pinctrl-1 = <0x97>;
			dmas = <0x94 0x0c 0x94 0x0d>;
			dma-names = "tx", "rx";
			#address-cells = <0x01>;
			#size-cells = <0x00>;
			status = "disabled";
		};

		i2c@7577000 {
			compatible = "qcom,i2c-qup-v2.2.1";
			reg = <0x7577000 0x1000>;
			interrupts = <0x00 0x61 0x04>;
			clocks = <0x1c 0x76 0x1c 0x6d>;
			clock-names = "core", "iface";
			pinctrl-names = "default", "sleep";
			pinctrl-0 = <0x98>;
			pinctrl-1 = <0x99>;
			dmas = <0x94 0x10 0x94 0x11>;
			dma-names = "tx", "rx";
			#address-cells = <0x01>;
			#size-cells = <0x00>;
			status = "disabled";
		};

		i2c@757a000 {
			compatible = "qcom,i2c-qup-v2.2.1";
			reg = <0x757a000 0x1000>;
			interrupts = <0x00 0x64 0x04>;
			clocks = <0x1c 0x7f 0x1c 0x6d>;
			clock-names = "core", "iface";
			pinctrl-names = "default", "sleep";
			pinctrl-0 = <0x9a>;
			pinctrl-1 = <0x9b>;
			dmas = <0x94 0x16 0x94 0x17>;
			dma-names = "tx", "rx";
			#address-cells = <0x01>;
			#size-cells = <0x00>;
			status = "disabled";
		};

		dma-controller@7584000 {
			compatible = "qcom,bam-v1.7.0";
			reg = <0x7584000 0x2b000>;
			interrupts = <0x00 0xef 0x04>;
			clocks = <0x1c 0x81>;
			clock-names = "bam_clk";
			qcom,controlled-remotely;
			#dma-cells = <0x01>;
			qcom,ee = <0x00>;
			phandle = <0x9e>;
		};

		serial@75b0000 {
			compatible = "qcom,msm-uartdm-v1.4", "qcom,msm-uartdm";
			reg = <0x75b0000 0x1000>;
			interrupts = <0x00 0x72 0x04>;
			clocks = <0x1c 0x88 0x1c 0x81>;
			clock-names = "core", "iface";
			status = "disabled";
		};

		serial@75b1000 {
			compatible = "qcom,msm-uartdm-v1.4", "qcom,msm-uartdm";
			reg = <0x75b1000 0x1000>;
			interrupts = <0x00 0x73 0x04>;
			clocks = <0x1c 0x8b 0x1c 0x81>;
			clock-names = "core", "iface";
			status = "disabled";
		};

		i2c@75b5000 {
			compatible = "qcom,i2c-qup-v2.2.1";
			reg = <0x75b5000 0x1000>;
			interrupts = <0x00 0x65 0x04>;
			clocks = <0x1c 0x84 0x1c 0x81>;
			clock-names = "core", "iface";
			pinctrl-names = "default", "sleep";
			pinctrl-0 = <0x9c>;
			pinctrl-1 = <0x9d>;
			dmas = <0x9e 0x0c 0x9e 0x0d>;
			dma-names = "tx", "rx";
			#address-cells = <0x01>;
			#size-cells = <0x00>;
			status = "disabled";
		};

		i2c@75b6000 {
			compatible = "qcom,i2c-qup-v2.2.1";
			reg = <0x75b6000 0x1000>;
			interrupts = <0x00 0x66 0x04>;
			clocks = <0x1c 0x87 0x1c 0x81>;
			clock-names = "core", "iface";
			pinctrl-names = "default", "sleep";
			pinctrl-0 = <0x9f>;
			pinctrl-1 = <0xa0>;
			dmas = <0x9e 0x0e 0x9e 0x0f>;
			dma-names = "tx", "rx";
			#address-cells = <0x01>;
			#size-cells = <0x00>;
			status = "okay";
			clock-frequency = <0x61a80>;

			nfc@28 {
				compatible = "nxp,nxp-nci-i2c";
				reg = <0x28>;
				interrupt-parent = <0x3c>;
				interrupts = <0x09 0x04>;
				enable-gpios = <0x3c 0x0c 0x00>;
				firmware-gpios = <0x3c 0x15 0x00>;
				pinctrl-names = "default";
				pinctrl-0 = <0xa1>;
			};
		};

		i2c@75b7000 {
			compatible = "qcom,i2c-qup-v2.2.1";
			reg = <0x75b7000 0x1000>;
			interrupts = <0x00 0x67 0x04>;
			clocks = <0x1c 0x8a 0x1c 0x81>;
			clock-names = "core", "iface";
			clock-frequency = <0x61a80>;
			pinctrl-names = "default", "sleep";
			pinctrl-0 = <0xa2>;
			pinctrl-1 = <0xa3>;
			dmas = <0x9e 0x10 0x9e 0x11>;
			dma-names = "tx", "rx";
			#address-cells = <0x01>;
			#size-cells = <0x00>;
			status = "okay";

			typec@47 {
				compatible = "ti,tusb320l";
				reg = <0x47>;
				interrupt-parent = <0x3c>;
				interrupts = <0x3f 0x02>;
				phandle = <0x88>;
			};

			drv2604@5a {
				compatible = "ti,drv2604";
				reg = <0x5a>;
				enable-gpio = <0x3c 0x5d 0x00>;
				mode = <0x00>;
				library-sel = <0x06>;
				pinctrl-names = "default", "sleep";
				pinctrl-0 = <0xa4>;
				pinctrl-1 = <0xa5>;
			};

			lp5562@30 {
				compatible = "ti,lp5562";
				reg = <0x30>;
				#address-cells = <0x01>;
				#size-cells = <0x00>;
				enable-gpios = <0x45 0x07 0x01>;
				clock-mode = [02];
				label = "button-backlight";

				led@0 {
					reg = <0x00>;
					chan-name = "button-backlight";
					led-cur = [32];
					max-cur = [c8];
				};

				led@1 {
					reg = <0x01>;
					chan-name = "button-backlight1";
					led-cur = [32];
					max-cur = [c8];
				};
			};
		};

		i2c@75b9000 {
			compatible = "qcom,i2c-qup-v2.2.1";
			reg = <0x75b9000 0x1000>;
			interrupts = <0x00 0x69 0x04>;
			clocks = <0x1c 0x90 0x1c 0x81>;
			clock-names = "core", "iface";
			pinctrl-names = "default";
			pinctrl-0 = <0xa6>;
			dmas = <0x9e 0x14 0x9e 0x15>;
			dma-names = "tx", "rx";
			#address-cells = <0x01>;
			#size-cells = <0x00>;
			status = "disabled";
		};

		i2c@75ba000 {
			compatible = "qcom,i2c-qup-v2.2.1";
			reg = <0x75ba000 0x1000>;
			interrupts = <0x00 0x6a 0x04>;
			clocks = <0x1c 0x93 0x1c 0x81>;
			clock-names = "core", "iface";
			pinctrl-names = "default", "sleep";
			pinctrl-0 = <0xa7>;
			pinctrl-1 = <0xa8>;
			dmas = <0x9e 0x16 0x9e 0x17>;
			dma-names = "tx", "rx";
			#address-cells = <0x01>;
			#size-cells = <0x00>;
			status = "okay";

			synaptics@20 {
				compatible = "syna,rmi4-i2c";
				reg = <0x20>;
				#address-cells = <0x01>;
				#size-cells = <0x00>;
				interrupt-parent = <0x3c>;
				interrupts = <0x7d 0x08>;
				vio-supply = <0xa9>;
				vdd-supply = <0xaa>;
				reset-gpios = <0x3c 0x59 0x01>;
				pinctrl-names = "default", "sleep";
				pinctrl-0 = <0xab>;
				pinctrl-1 = <0xac>;
			};
		};

		spi@75ba000 {
			compatible = "qcom,spi-qup-v2.2.1";
			reg = <0x75ba000 0x600>;
			interrupts = <0x00 0x6a 0x04>;
			clocks = <0x1c 0x92 0x1c 0x81>;
			clock-names = "core", "iface";
			pinctrl-names = "default", "sleep";
			pinctrl-0 = <0xad>;
			pinctrl-1 = <0xae>;
			dmas = <0x9e 0x16 0x9e 0x17>;
			dma-names = "tx", "rx";
			#address-cells = <0x01>;
			#size-cells = <0x00>;
			status = "disabled";
		};

		usb@76f8800 {
			compatible = "qcom,msm8996-dwc3", "qcom,dwc3";
			reg = <0x76f8800 0x400>;
			#address-cells = <0x01>;
			#size-cells = <0x01>;
			ranges;
			interrupts = <0x00 0x8c 0x04 0x00 0x160 0x04 0x00 0x8b 0x04>;
			interrupt-names = "pwr_event", "qusb2_phy", "hs_phy_irq";
			clocks = <0x1c 0x55 0x1c 0x60 0x1c 0x62 0x1c 0x61 0x1c 0x63>;
			clock-names = "cfg_noc", "core", "iface", "sleep", "mock_utmi";
			assigned-clocks = <0x1c 0x62 0x1c 0x60>;
			assigned-clock-rates = <0x124f800 0x3938700>;
			interconnects = <0xaf 0x04 0x2f 0x04 0x2f 0x00 0xaf 0x09>;
			interconnect-names = "usb-ddr", "apps-usb";
			power-domains = <0x1c 0x04>;
			qcom,select-utmi-as-pipe-clk;
			status = "disabled";

			usb@7600000 {
				compatible = "snps,dwc3";
				reg = <0x7600000 0xcc00>;
				interrupts = <0x00 0x8a 0x04>;
				phys = <0xb0>;
				phy-names = "usb2-phy";
				maximum-speed = "high-speed";
				snps,dis_u2_susphy_quirk;
				snps,dis_enblslpm_quirk;
			};
		};

		dma-controller@9184000 {
			compatible = "qcom,bam-v1.7.0";
			qcom,controlled-remotely;
			reg = <0x9184000 0x32000>;
			num-channels = <0x1f>;
			interrupts = <0x00 0xa4 0x04>;
			#dma-cells = <0x01>;
			qcom,ee = <0x01>;
			qcom,num-ees = <0x02>;
			phandle = <0xb1>;
		};

		slim-ngd@91c0000 {
			compatible = "qcom,slim-ngd-v1.5.0";
			reg = <0x91c0000 0x2c000>;
			interrupts = <0x00 0xa3 0x04>;
			dmas = <0xb1 0x03 0xb1 0x04>;
			dma-names = "rx", "tx";
			#address-cells = <0x01>;
			#size-cells = <0x00>;
			status = "okay";

			slim@1 {
				reg = <0x01>;
				#address-cells = <0x02>;
				#size-cells = <0x00>;

				tas-ifd@0,0 {
					compatible = "slim217,1a0";
					reg = <0x00 0x00>;
					phandle = <0xb5>;
				};

				codec@1,0 {
					compatible = "slim217,1a0";
					reg = <0x01 0x00>;
					clock-names = "mclk", "slimbus";
					clocks = <0xb2 0x1f 0x0a>;
					interrupt-parent = <0x3c>;
					interrupts = <0x36 0x04 0x35 0x04>;
					interrupt-names = "intr1", "intr2";
					interrupt-controller;
					#interrupt-cells = <0x01>;
					pinctrl-0 = <0xb3 0xb4>;
					pinctrl-names = "default";
					reset-gpios = <0x3c 0x40 0x01>;
					slim-ifc-dev = <0xb5>;
					#sound-dai-cells = <0x01>;
					vdd-buck-supply = <0x19>;
					vdd-buck-sido-supply = <0x19>;
					vdd-rx-supply = <0x19>;
					vdd-tx-supply = <0x19>;
					vdd-vbat-supply = <0x14>;
					vdd-micbias-supply = <0x18>;
					vdd-io-supply = <0x19>;
					phandle = <0xbd>;
				};
			};
		};

		remoteproc@9300000 {
			compatible = "qcom,msm8996-adsp-pil";
			reg = <0x9300000 0x80000>;
			interrupts-extended = <0x01 0x00 0xa2 0x01 0xb6 0x00 0x01 0xb6 0x01 0x01 0xb6 0x02 0x01 0xb6 0x03 0x01>;
			interrupt-names = "wdog", "fatal", "ready", "handover", "stop-ack";
			clocks = <0x1f 0x00>;
			clock-names = "xo";
			memory-region = <0xb7>;
			qcom,smem-states = <0xb8 0x00>;
			qcom,smem-state-names = "stop";
			power-domains = <0x60 0x00>;
			power-domain-names = "cx";
			status = "okay";
			firmware-name = "qcom/msm8996/gemini/adsp.mbn";

			glink-edge {
				interrupts = <0x00 0x9d 0x01>;
				label = "lpass";
				qcom,remote-pid = <0x02>;
				mboxes = <0x11 0x09>;
			};

			smd-edge {
				interrupts = <0x00 0x9c 0x01>;
				label = "lpass";
				mboxes = <0x11 0x08>;
				qcom,smd-edge = <0x01>;
				qcom,remote-pid = <0x02>;

				apr {
					power-domains = <0x1c 0x02>;
					compatible = "qcom,apr-v2";
					qcom,smd-channels = "apr_audio_svc";
					qcom,domain = <0x04>;
					#address-cells = <0x01>;
					#size-cells = <0x00>;

					service@3 {
						reg = <0x03>;
						compatible = "qcom,q6core";
					};

					service@4 {
						compatible = "qcom,q6afe";
						reg = <0x04>;

						dais {
							compatible = "qcom,q6afe-dais";
							#address-cells = <0x01>;
							#size-cells = <0x00>;
							#sound-dai-cells = <0x01>;
							phandle = <0xbb>;

							dai@1 {
								reg = <0x01>;
							};
						};
					};

					service@7 {
						compatible = "qcom,q6asm";
						reg = <0x07>;

						dais {
							compatible = "qcom,q6asm-dais";
							#address-cells = <0x01>;
							#size-cells = <0x00>;
							#sound-dai-cells = <0x01>;
							iommus = <0xb9 0x01>;
							phandle = <0xba>;

							dai@0 {
								reg = <0x00>;
							};

							dai@1 {
								reg = <0x01>;
							};

							dai@2 {
								reg = <0x02>;
							};

							dai@3 {
								reg = <0x03>;
							};

							dai@4 {
								reg = <0x04>;
							};

							dai@5 {
								reg = <0x05>;
							};
						};
					};

					service@8 {
						compatible = "qcom,q6adm";
						reg = <0x08>;

						routing {
							compatible = "qcom,q6adm-routing";
							#sound-dai-cells = <0x00>;
							phandle = <0xbc>;
						};
					};
				};

				fastrpc {
					compatible = "qcom,fastrpc";
					qcom,smd-channels = "fastrpcsmd-apps-dsp";
					label = "adsp";
					qcom,non-secure-domain;
					#address-cells = <0x01>;
					#size-cells = <0x00>;

					cb@5 {
						compatible = "qcom,fastrpc-compute-cb";
						reg = <0x05>;
						iommus = <0xb9 0x05>;
					};

					cb@6 {
						compatible = "qcom,fastrpc-compute-cb";
						reg = <0x06>;
						iommus = <0xb9 0x06>;
					};

					cb@7 {
						compatible = "qcom,fastrpc-compute-cb";
						reg = <0x07>;
						iommus = <0xb9 0x07>;
					};

					cb@8 {
						compatible = "qcom,fastrpc-compute-cb";
						reg = <0x08>;
						iommus = <0xb9 0x08>;
					};

					cb@9 {
						compatible = "qcom,fastrpc-compute-cb";
						reg = <0x09>;
						iommus = <0xb9 0x09>;
					};

					cb@10 {
						compatible = "qcom,fastrpc-compute-cb";
						reg = <0x0a>;
						iommus = <0xb9 0x0a>;
					};

					cb@11 {
						compatible = "qcom,fastrpc-compute-cb";
						reg = <0x0b>;
						iommus = <0xb9 0x0b>;
					};

					cb@12 {
						compatible = "qcom,fastrpc-compute-cb";
						reg = <0x0c>;
						iommus = <0xb9 0x0c>;
					};
				};
			};
		};

		mailbox@9820000 {
			compatible = "qcom,msm8996-apcs-hmss-global";
			reg = <0x9820000 0x1000>;
			#mbox-cells = <0x01>;
			#clock-cells = <0x00>;
			phandle = <0x11>;
		};

		timer@9840000 {
			#address-cells = <0x01>;
			#size-cells = <0x01>;
			ranges;
			compatible = "arm,armv7-timer-mem";
			reg = <0x9840000 0x1000>;
			clock-frequency = <0x124f800>;

			frame@9850000 {
				frame-number = <0x00>;
				interrupts = <0x00 0x1f 0x04 0x00 0x1e 0x04>;
				reg = <0x9850000 0x1000 0x9860000 0x1000>;
			};

			frame@9870000 {
				frame-number = <0x01>;
				interrupts = <0x00 0x20 0x04>;
				reg = <0x9870000 0x1000>;
				status = "disabled";
			};

			frame@9880000 {
				frame-number = <0x02>;
				interrupts = <0x00 0x21 0x04>;
				reg = <0x9880000 0x1000>;
				status = "disabled";
			};

			frame@9890000 {
				frame-number = <0x03>;
				interrupts = <0x00 0x22 0x04>;
				reg = <0x9890000 0x1000>;
				status = "disabled";
			};

			frame@98a0000 {
				frame-number = <0x04>;
				interrupts = <0x00 0x23 0x04>;
				reg = <0x98a0000 0x1000>;
				status = "disabled";
			};

			frame@98b0000 {
				frame-number = <0x05>;
				interrupts = <0x00 0x24 0x04>;
				reg = <0x98b0000 0x1000>;
				status = "disabled";
			};

			frame@98c0000 {
				frame-number = <0x06>;
				interrupts = <0x00 0x25 0x04>;
				reg = <0x98c0000 0x1000>;
				status = "disabled";
			};
		};

		syscon@9a10000 {
			compatible = "syscon";
			reg = <0x9a10000 0x1000>;
			phandle = <0x47>;
		};

		clock-controller@9a11000 {
			compatible = "qcom,msm8996-cbf";
			reg = <0x9a11000 0x10000>;
			clocks = <0x1f 0x01 0x11>;
			#clock-cells = <0x00>;
			#interconnect-cells = <0x01>;
			phandle = <0x04>;
		};

		interrupt-controller@9bc0000 {
			compatible = "qcom,msm8996-gic-v3", "arm,gic-v3";
			#address-cells = <0x00>;
			#interrupt-cells = <0x03>;
			interrupt-controller;
			#redistributor-regions = <0x01>;
			redistributor-stride = <0x00 0x40000>;
			reg = <0x9bc0000 0x10000 0x9c00000 0x100000>;
			interrupts = <0x01 0x09 0x04>;
			phandle = <0x01>;
		};
	};

	sound {
		compatible = "qcom,apq8096-sndcard";
		audio-routing = "RX_BIAS", "MCLK", "AMIC1", "MIC BIAS1", "AMIC2", "MIC BIAS2", "AMIC3", "MIC BIAS4", "AMIC4", "MIC BIAS4";
		model = "gemini";

		mm1-dai-link {
			link-name = "MultiMedia1";

			cpu {
				sound-dai = <0xba 0x00>;
			};
		};

		mm2-dai-link {
			link-name = "MultiMedia2";

			cpu {
				sound-dai = <0xba 0x01>;
			};
		};

		mm3-dai-link {
			link-name = "MultiMedia3";

			cpu {
				sound-dai = <0xba 0x02>;
			};
		};

		mm4-dai-link {
			link-name = "MultiMedia4";

			cpu {
				sound-dai = <0xba 0x03>;
			};
		};

		mm5-dai-link {
			link-name = "MultiMedia5";

			cpu {
				sound-dai = <0xba 0x04>;
			};
		};

		mm6-dai-link {
			link-name = "MultiMedia6";

			cpu {
				sound-dai = <0xba 0x05>;
			};
		};

		wcd-aif1-pb-dai-link {
			link-name = "AIF1_PB";

			cpu {
				sound-dai = <0xbb 0x0a>;
			};

			platform {
				sound-dai = <0xbc>;
			};

			codec {
				sound-dai = <0xbd 0x00>;
			};
		};

		wcd-aif4-pb-dai-link {
			link-name = "AIF4_PB";

			cpu {
				sound-dai = <0xbb 0x0e>;
			};

			platform {
				sound-dai = <0xbc>;
			};

			codec {
				sound-dai = <0xbd 0x06>;
			};
		};

		wcd-aif1-cap-dai-link {
			link-name = "AIF1_CAP";

			cpu {
				sound-dai = <0xbb 0x03>;
			};

			platform {
				sound-dai = <0xbc>;
			};

			codec {
				sound-dai = <0xbd 0x01>;
			};
		};

		wcd-aif2-cap-dai-link {
			link-name = "AIF2_CAP";

			cpu {
				sound-dai = <0xbb 0x05>;
			};

			platform {
				sound-dai = <0xbc>;
			};

			codec {
				sound-dai = <0xbd 0x03>;
			};
		};

		wcd-aif3-cap-dai-link {
			link-name = "AIF3_CAP";

			cpu {
				sound-dai = <0xbb 0x07>;
			};

			platform {
				sound-dai = <0xbc>;
			};

			codec {
				sound-dai = <0xbd 0x05>;
			};
		};

		wcd-aif4-cap-dai-link {
			link-name = "AIF4_CAP";

			cpu {
				sound-dai = <0xbb 0x09>;
			};

			platform {
				sound-dai = <0xbc>;
			};

			codec {
				sound-dai = <0xbd 0x07>;
			};
		};
	};

	thermal-zones {

		cpu0-thermal {
			polling-delay-passive = <0xfa>;
			thermal-sensors = <0xbe 0x03>;

			trips {

				trip-point0 {
					temperature = <0x14c08>;
					hysteresis = <0x7d0>;
					type = "passive";
					phandle = <0xbf>;
				};

				trip-point1 {
					temperature = <0x15f90>;
					hysteresis = <0x7d0>;
					type = "passive";
					phandle = <0xc0>;
				};

				cpu-crit {
					temperature = <0x1adb0>;
					hysteresis = <0x7d0>;
					type = "critical";
				};
			};

			cooling-maps {

				map0 {
					trip = <0xbf>;
					cooling-device = <0x09 0xffffffff 0xffffffff 0x0a 0xffffffff 0xffffffff>;
				};

				map1 {
					trip = <0xc0>;
					cooling-device = <0x09 0xffffffff 0xffffffff 0x0a 0xffffffff 0xffffffff>;
				};
			};
		};

		cpu1-thermal {
			polling-delay-passive = <0xfa>;
			thermal-sensors = <0xbe 0x05>;

			trips {

				trip-point0 {
					temperature = <0x14c08>;
					hysteresis = <0x7d0>;
					type = "passive";
					phandle = <0xc1>;
				};

				trip-point1 {
					temperature = <0x15f90>;
					hysteresis = <0x7d0>;
					type = "passive";
					phandle = <0xc2>;
				};

				cpu-crit {
					temperature = <0x1adb0>;
					hysteresis = <0x7d0>;
					type = "critical";
				};
			};

			cooling-maps {

				map0 {
					trip = <0xc1>;
					cooling-device = <0x09 0xffffffff 0xffffffff 0x0a 0xffffffff 0xffffffff>;
				};

				map1 {
					trip = <0xc2>;
					cooling-device = <0x09 0xffffffff 0xffffffff 0x0a 0xffffffff 0xffffffff>;
				};
			};
		};

		cpu2-thermal {
			polling-delay-passive = <0xfa>;
			thermal-sensors = <0xbe 0x08>;

			trips {

				trip-point0 {
					temperature = <0x14c08>;
					hysteresis = <0x7d0>;
					type = "passive";
					phandle = <0xc3>;
				};

				trip-point1 {
					temperature = <0x15f90>;
					hysteresis = <0x7d0>;
					type = "passive";
					phandle = <0xc4>;
				};

				cpu-crit {
					temperature = <0x1adb0>;
					hysteresis = <0x7d0>;
					type = "critical";
				};
			};

			cooling-maps {

				map0 {
					trip = <0xc3>;
					cooling-device = <0x0b 0xffffffff 0xffffffff 0x0c 0xffffffff 0xffffffff>;
				};

				map1 {
					trip = <0xc4>;
					cooling-device = <0x0b 0xffffffff 0xffffffff 0x0c 0xffffffff 0xffffffff>;
				};
			};
		};

		cpu3-thermal {
			polling-delay-passive = <0xfa>;
			thermal-sensors = <0xbe 0x0a>;

			trips {

				trip-point0 {
					temperature = <0x14c08>;
					hysteresis = <0x7d0>;
					type = "passive";
					phandle = <0xc5>;
				};

				trip-point1 {
					temperature = <0x15f90>;
					hysteresis = <0x7d0>;
					type = "passive";
					phandle = <0xc6>;
				};

				cpu-crit {
					temperature = <0x1adb0>;
					hysteresis = <0x7d0>;
					type = "critical";
				};
			};

			cooling-maps {

				map0 {
					trip = <0xc5>;
					cooling-device = <0x0b 0xffffffff 0xffffffff 0x0c 0xffffffff 0xffffffff>;
				};

				map1 {
					trip = <0xc6>;
					cooling-device = <0x0b 0xffffffff 0xffffffff 0x0c 0xffffffff 0xffffffff>;
				};
			};
		};

		gpu-top-thermal {
			polling-delay-passive = <0xfa>;
			thermal-sensors = <0xc7 0x06>;

			trips {

				trip-point0 {
					temperature = <0x15f90>;
					hysteresis = <0x7d0>;
					type = "passive";
					phandle = <0xc8>;
				};
			};

			cooling-maps {

				map0 {
					trip = <0xc8>;
					cooling-device = <0xc9 0xffffffff 0xffffffff>;
				};
			};
		};

		gpu-bottom-thermal {
			polling-delay-passive = <0xfa>;
			thermal-sensors = <0xc7 0x07>;

			trips {

				trip-point0 {
					temperature = <0x15f90>;
					hysteresis = <0x7d0>;
					type = "passive";
					phandle = <0xca>;
				};
			};

			cooling-maps {

				map0 {
					trip = <0xca>;
					cooling-device = <0xc9 0xffffffff 0xffffffff>;
				};
			};
		};

		m4m-thermal {
			polling-delay-passive = <0xfa>;
			thermal-sensors = <0xbe 0x01>;

			trips {

				trip-point0 {
					temperature = <0x15f90>;
					hysteresis = <0x7d0>;
					type = "hot";
				};
			};
		};

		l3-or-venus-thermal {
			polling-delay-passive = <0xfa>;
			thermal-sensors = <0xbe 0x02>;

			trips {

				trip-point0 {
					temperature = <0x15f90>;
					hysteresis = <0x7d0>;
					type = "hot";
				};
			};
		};

		cluster0-l2-thermal {
			polling-delay-passive = <0xfa>;
			thermal-sensors = <0xbe 0x07>;

			trips {

				trip-point0 {
					temperature = <0x15f90>;
					hysteresis = <0x7d0>;
					type = "hot";
				};
			};
		};

		cluster1-l2-thermal {
			polling-delay-passive = <0xfa>;
			thermal-sensors = <0xbe 0x0c>;

			trips {

				trip-point0 {
					temperature = <0x15f90>;
					hysteresis = <0x7d0>;
					type = "hot";
				};
			};
		};

		camera-thermal {
			polling-delay-passive = <0xfa>;
			thermal-sensors = <0xc7 0x01>;

			trips {

				trip-point0 {
					temperature = <0x15f90>;
					hysteresis = <0x7d0>;
					type = "hot";
				};
			};
		};

		q6-dsp-thermal {
			polling-delay-passive = <0xfa>;
			thermal-sensors = <0xc7 0x02>;

			trips {

				trip-point0 {
					temperature = <0x15f90>;
					hysteresis = <0x7d0>;
					type = "hot";
				};
			};
		};

		mem-thermal {
			polling-delay-passive = <0xfa>;
			thermal-sensors = <0xc7 0x03>;

			trips {

				trip-point0 {
					temperature = <0x15f90>;
					hysteresis = <0x7d0>;
					type = "hot";
				};
			};
		};

		modemtx-thermal {
			polling-delay-passive = <0xfa>;
			thermal-sensors = <0xc7 0x04>;

			trips {

				trip-point0 {
					temperature = <0x15f90>;
					hysteresis = <0x7d0>;
					type = "hot";
				};
			};
		};

		pm8994-thermal {
			polling-delay-passive = <0xfa>;
			thermal-sensors = <0xcb>;

			trips {

				pm8994-alert0 {
					temperature = <0x17318>;
					hysteresis = <0x7d0>;
					type = "passive";
				};

				pm8994-crit {
					temperature = <0x1e848>;
					hysteresis = <0x7d0>;
					type = "critical";
				};
			};
		};
	};

	timer {
		compatible = "arm,armv8-timer";
		interrupts = <0x01 0x0d 0x08 0x01 0x0e 0x08 0x01 0x0b 0x08 0x01 0x0a 0x08>;
	};

	battery {
		compatible = "simple-battery";
		voltage-min-design-microvolt = <0x33e140>;
		voltage-max-design-microvolt = <0x432380>;
		charge-full-design-microamp-hours = <0x2dc6c0>;
		constant-charge-current-max-microamp = <0x2dc6c0>;
		phandle = <0x48>;
	};

	divclk1 {
		compatible = "gpio-gate-clock";
		clocks = <0x1f 0x2e>;
		#clock-cells = <0x00>;
		enable-gpios = <0x45 0x0f 0x00>;
		pinctrl-names = "default";
		pinctrl-0 = <0xcc>;
		phandle = <0xb2>;
	};

	divclk4 {
		compatible = "fixed-clock";
		#clock-cells = <0x00>;
		clock-frequency = <0x8000>;
		clock-output-names = "divclk4";
		pinctrl-names = "default";
		pinctrl-0 = <0xcd>;
		phandle = <0x95>;
	};

	gpio-keys {
		compatible = "gpio-keys";

		key-vol-up {
			label = "Volume Up";
			gpios = <0x45 0x02 0x01>;
			linux,code = <0x73>;
			wakeup-source;
			debounce-interval = <0x0f>;
		};

		key-dome {
			label = "Home";
			gpios = <0x3c 0x22 0x01>;
			linux,code = <0x66>;
			wakeup-source;
			debounce-interval = <0x0f>;
		};
	};

	irled {
		compatible = "pwm-ir-tx";
		pwms = <0xce 0x01 0xf4240>;
		pinctrl-names = "default";
		pinctrl-0 = <0xcf>;
	};

	vph-pwr-regulator {
		compatible = "regulator-fixed";
		regulator-name = "vph_pwr";
		regulator-min-microvolt = <0x39fbc0>;
		regulator-max-microvolt = <0x39fbc0>;
		regulator-always-on;
		regulator-boot-on;
		phandle = <0x14>;
	};

	vdd-cam-1p1 {
		compatible = "regulator-fixed";
		regulator-name = "vdd_cam_1p1";
		regulator-min-microvolt = <0x10c8e0>;
		regulator-max-microvolt = <0x10c8e0>;
		vin-supply = <0x16>;
		regulator-allow-set-load;
		gpio = <0x3c 0x56 0x00>;
		enable-active-high;
		pinctrl-names = "default";
		pinctrl-0 = <0xd0>;
	};

	vdd-3v2-tp {
		compatible = "regulator-fixed";
		regulator-name = "vdd_3v2_tp";
		regulator-min-microvolt = <0x30d400>;
		regulator-max-microvolt = <0x30d400>;
		startup-delay-us = <0xfa0>;
		vin-supply = <0x14>;
		gpio = <0x3c 0x49 0x00>;
		enable-active-high;
		phandle = <0xaa>;
	};

	rome-vreg {
		compatible = "regulator-fixed";
		regulator-name = "vdd_3v3";
		regulator-min-microvolt = <0x325aa0>;
		regulator-max-microvolt = <0x325aa0>;
		startup-delay-us = <0xfa0>;
		vin-supply = <0x18>;
		gpio = <0x45 0x09 0x00>;
		enable-active-high;
		pinctrl-names = "default";
		pinctrl-0 = <0xd1>;
		regulator-always-on;
	};

	wlan-en-1-8v {
		compatible = "regulator-fixed";
		regulator-name = "wlan-en-regulator";
		regulator-min-microvolt = <0x1b7740>;
		regulator-max-microvolt = <0x1b7740>;
		gpio = <0x45 0x08 0x00>;
		startup-delay-us = <0x11170>;
		enable-active-high;
		pinctrl-names = "default";
		pinctrl-0 = <0xd2>;
		phandle = <0x4e>;
	};

	divclk2 {
		compatible = "fixed-clock";
		#clock-cells = <0x00>;
		clock-frequency = <0x8000>;
		clock-output-names = "divclk2";
		pinctrl-names = "default";
		pinctrl-0 = <0xd3>;
	};
};
